VERSION ""

NS_ :

BS_:

BU_: RoomController HomeAssistantESP
VAL_TABLE_ DMAS_VAR_TYPE_TABLE 8 "DMAS_TES" 7 "DMAS_TBS" 6 "DMAS_TF32S" 5 "DMAS_TS32" 4 "DMAS_TS16" 3 "DMAS_TS8" 2 "DMAS_TU32" 1 "DMAS_TU16" 0 "DMAS_TU8" ;
VAL_TABLE_ DMAS_MODE_TABLE 4 "DMAS_MODE_STOPOVERWRITE" 3 "DMAS_MODE_OVERWRITE" 2 "DMAS_MODE_WRITE" 1 "DMAS_MODE_STOP_READ" 0 "DMAS_MODE_READ_REQ" ;
VAL_TABLE_ DMAS_TIME_TABLE 5 "stream 5000ms" 4 "stream 1000ms" 3 "stream 500ms" 2 "stream 100ms" 1 "stream 50ms" 0 "stream 10ms" ;

BO_ 3221225472 VECTOR__INDEPENDENT_SIG_MSG: 0 Vector__XXX
 SG_ DMAS_var_type : 0|8@1+ (1,0) [0|255] "" Vector__XXX

BO_ 48 Lux_Measurement: 8 Vector__XXX
 SG_ Lux : 0|32@1- (1,0) [-3.4E+038|3.4E+038] "" Vector__XXX

BO_ 273 RelayFeedback_64_127: 8 Vector__XXX
 SG_ RelaySts_125 : 63|1@1+ (1,0) [0|1] "" Vector__XXX
 SG_ RelaySts_124 : 62|1@1+ (1,0) [0|1] "" Vector__XXX
 SG_ RelaySts_123 : 61|1@1+ (1,0) [0|1] "" Vector__XXX
 SG_ RelaySts_122 : 60|1@1+ (1,0) [0|1] "" Vector__XXX
 SG_ RelaySts_121 : 59|1@1+ (1,0) [0|1] "" Vector__XXX
 SG_ RelaySts_120 : 58|1@1+ (1,0) [0|1] "" Vector__XXX
 SG_ RelaySts_119 : 57|1@1+ (1,0) [0|1] "" Vector__XXX
 SG_ RelaySts_118 : 56|1@1+ (1,0) [0|1] "" Vector__XXX
 SG_ RelaySts_117 : 55|1@1+ (1,0) [0|1] "" Vector__XXX
 SG_ RelaySts_116 : 54|1@1+ (1,0) [0|1] "" Vector__XXX
 SG_ RelaySts_115 : 53|1@1+ (1,0) [0|1] "" Vector__XXX
 SG_ RelaySts_114 : 52|1@1+ (1,0) [0|1] "" Vector__XXX
 SG_ RelaySts_113 : 51|1@1+ (1,0) [0|1] "" Vector__XXX
 SG_ RelaySts_112 : 50|1@1+ (1,0) [0|1] "" Vector__XXX
 SG_ RelaySts_111 : 49|1@1+ (1,0) [0|1] "" Vector__XXX
 SG_ RelaySts_110 : 48|1@1+ (1,0) [0|1] "" Vector__XXX
 SG_ RelaySts_110 : 47|1@1+ (1,0) [0|1] "" Vector__XXX
 SG_ RelaySts_109 : 46|1@1+ (1,0) [0|1] "" Vector__XXX
 SG_ RelaySts_108 : 45|1@1+ (1,0) [0|1] "" Vector__XXX
 SG_ RelaySts_107 : 44|1@1+ (1,0) [0|1] "" Vector__XXX
 SG_ RelaySts_106 : 43|1@1+ (1,0) [0|1] "" Vector__XXX
 SG_ RelaySts_105 : 42|1@1+ (1,0) [0|1] "" Vector__XXX
 SG_ RelaySts_104 : 41|1@1+ (1,0) [0|1] "" Vector__XXX
 SG_ RelaySts_103 : 40|1@1+ (1,0) [0|1] "" Vector__XXX
 SG_ RelaySts_102 : 39|1@1+ (1,0) [0|1] "" Vector__XXX
 SG_ RelaySts_101 : 38|1@1+ (1,0) [0|1] "" Vector__XXX
 SG_ RelaySts_100 : 37|1@1+ (1,0) [0|1] "" Vector__XXX
 SG_ RelaySts_99 : 36|1@1+ (1,0) [0|1] "" Vector__XXX
 SG_ RelaySts_98 : 35|1@1+ (1,0) [0|1] "" Vector__XXX
 SG_ RelaySts_97 : 34|1@1+ (1,0) [0|1] "" Vector__XXX
 SG_ RelaySts_96 : 33|1@1+ (1,0) [0|1] "" Vector__XXX
 SG_ RelaySts_95 : 32|1@1+ (1,0) [0|1] "" Vector__XXX
 SG_ RelaySts_94 : 31|1@1+ (1,0) [0|1] "" Vector__XXX
 SG_ RelaySts_93 : 30|1@1+ (1,0) [0|1] "" Vector__XXX
 SG_ RelaySts_92 : 29|1@1+ (1,0) [0|1] "" Vector__XXX
 SG_ RelaySts_91 : 28|1@1+ (1,0) [0|1] "" Vector__XXX
 SG_ RelaySts_90 : 27|1@1+ (1,0) [0|1] "" Vector__XXX
 SG_ RelaySts_80 : 26|1@1+ (1,0) [0|1] "" Vector__XXX
 SG_ RelaySts_89 : 25|1@1+ (1,0) [0|1] "" Vector__XXX
 SG_ RelaySts_88 : 24|1@1+ (1,0) [0|1] "" Vector__XXX
 SG_ RelaySts_87 : 23|1@1+ (1,0) [0|1] "" Vector__XXX
 SG_ RelaySts_86 : 22|1@1+ (1,0) [0|1] "" Vector__XXX
 SG_ RelaySts_85 : 21|1@1+ (1,0) [0|1] "" Vector__XXX
 SG_ RelaySts_84 : 20|1@1+ (1,0) [0|1] "" Vector__XXX
 SG_ RelaySts_83 : 19|1@1+ (1,0) [0|1] "" Vector__XXX
 SG_ RelaySts_82 : 18|1@1+ (1,0) [0|1] "" Vector__XXX
 SG_ RelaySts_81 : 17|1@1+ (1,0) [0|1] "" Vector__XXX
 SG_ RelaySts_80 : 16|1@1+ (1,0) [0|1] "" Vector__XXX
 SG_ RelaySts_79 : 15|1@1+ (1,0) [0|1] "" Vector__XXX
 SG_ RelaySts_78 : 14|1@1+ (1,0) [0|1] "" Vector__XXX
 SG_ RelaySts_77 : 13|1@1+ (1,0) [0|1] "" Vector__XXX
 SG_ RelaySts_76 : 12|1@1+ (1,0) [0|1] "" Vector__XXX
 SG_ RelaySts_75 : 11|1@1+ (1,0) [0|1] "" Vector__XXX
 SG_ RelaySts_74 : 10|1@1+ (1,0) [0|1] "" Vector__XXX
 SG_ RelaySts_73 : 9|1@1+ (1,0) [0|1] "" Vector__XXX
 SG_ RelaySts_72 : 8|1@1+ (1,0) [0|1] "" Vector__XXX
 SG_ RelaySts_71 : 7|1@1+ (1,0) [0|1] "" Vector__XXX
 SG_ RelaySts_70 : 6|1@1+ (1,0) [0|1] "" Vector__XXX
 SG_ RelaySts_69 : 5|1@1+ (1,0) [0|1] "" Vector__XXX
 SG_ RelaySts_68 : 4|1@1+ (1,0) [0|1] "" Vector__XXX
 SG_ RelaySts_67 : 3|1@1+ (1,0) [0|1] "" Vector__XXX
 SG_ RelaySts_66 : 2|1@1+ (1,0) [0|1] "" Vector__XXX
 SG_ RelaySts_65 : 1|1@1+ (1,0) [0|1] "" Vector__XXX
 SG_ RelaySts_64 : 0|1@1+ (1,0) [0|1] "" Vector__XXX

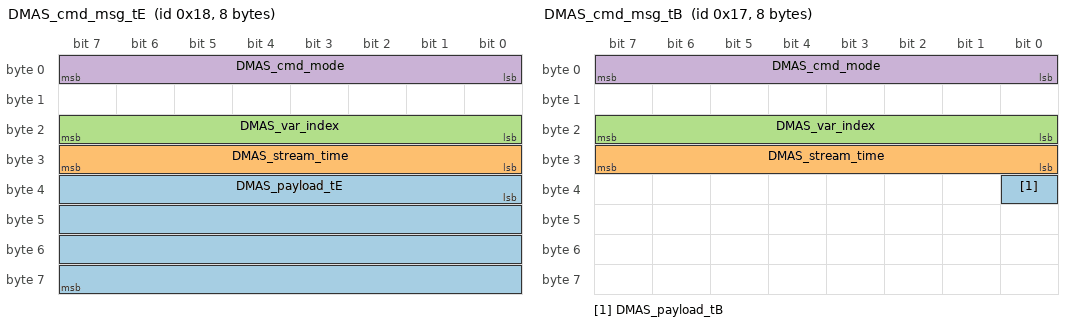
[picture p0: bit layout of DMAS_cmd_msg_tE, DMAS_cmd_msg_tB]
BO_ 24 DMAS_cmd_msg_tE: 8 Vector__XXX
 SG_ DMAS_payload_tE : 32|32@1+ (1,0) [0|4294967295] "" Vector__XXX
 SG_ DMAS_stream_time : 24|8@1+ (1,0) [0|255] "" Vector__XXX
 SG_ DMAS_var_index : 16|8@1+ (1,0) [0|255] "" Vector__XXX
 SG_ DMAS_cmd_mode : 0|8@1+ (1,0) [0|255] "" Vector__XXX

BO_ 23 DMAS_cmd_msg_tB: 8 Vector__XXX
 SG_ DMAS_payload_tB : 32|1@1+ (1,0) [0|1] "" Vector__XXX
 SG_ DMAS_stream_time : 24|8@1+ (1,0) [0|255] "" Vector__XXX
 SG_ DMAS_var_index : 16|8@1+ (1,0) [0|255] "" Vector__XXX
 SG_ DMAS_cmd_mode : 0|8@1+ (1,0) [0|255] "" Vector__XXX

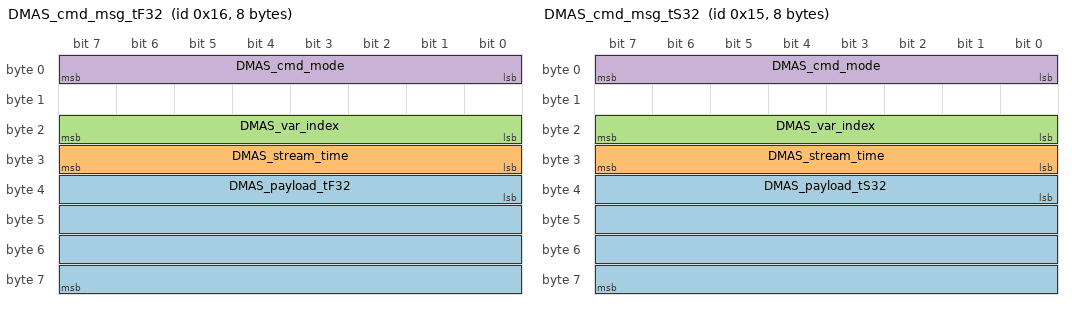
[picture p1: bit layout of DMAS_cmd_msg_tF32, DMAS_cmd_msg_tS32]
BO_ 22 DMAS_cmd_msg_tF32: 8 Vector__XXX
 SG_ DMAS_payload_tF32 : 32|32@1- (1,0) [-3.4E+038|3.4E+038] "" Vector__XXX
 SG_ DMAS_stream_time : 24|8@1+ (1,0) [0|255] "" Vector__XXX
 SG_ DMAS_var_index : 16|8@1+ (1,0) [0|255] "" Vector__XXX
 SG_ DMAS_cmd_mode : 0|8@1+ (1,0) [0|255] "" Vector__XXX

BO_ 21 DMAS_cmd_msg_tS32: 8 Vector__XXX
 SG_ DMAS_payload_tS32 : 32|32@1- (1,0) [-2147483648|2147483647] "" Vector__XXX
 SG_ DMAS_stream_time : 24|8@1+ (1,0) [0|255] "" Vector__XXX
 SG_ DMAS_var_index : 16|8@1+ (1,0) [0|255] "" Vector__XXX
 SG_ DMAS_cmd_mode : 0|8@1+ (1,0) [0|255] "" Vector__XXX

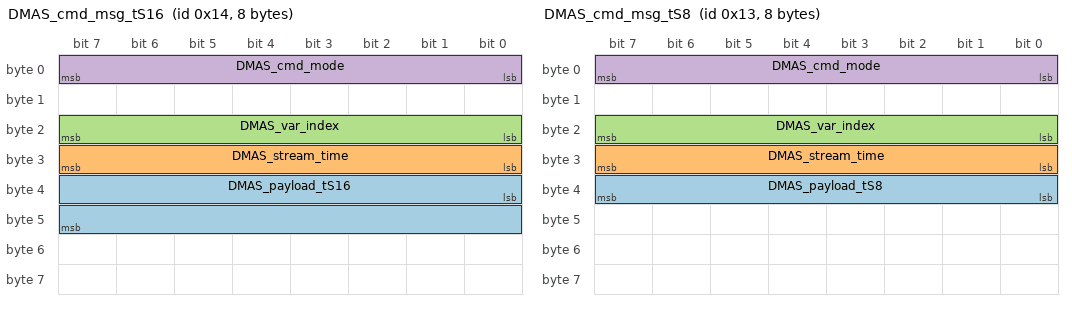
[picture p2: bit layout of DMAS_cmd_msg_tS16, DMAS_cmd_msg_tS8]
BO_ 20 DMAS_cmd_msg_tS16: 8 Vector__XXX
 SG_ DMAS_payload_tS16 : 32|16@1- (1,0) [-32768|32767] "" Vector__XXX
 SG_ DMAS_stream_time : 24|8@1+ (1,0) [0|255] "" Vector__XXX
 SG_ DMAS_var_index : 16|8@1+ (1,0) [0|255] "" Vector__XXX
 SG_ DMAS_cmd_mode : 0|8@1+ (1,0) [0|255] "" Vector__XXX

BO_ 19 DMAS_cmd_msg_tS8: 8 Vector__XXX
 SG_ DMAS_payload_tS8 : 32|8@1- (1,0) [-128|127] "" Vector__XXX
 SG_ DMAS_stream_time : 24|8@1+ (1,0) [0|255] "" Vector__XXX
 SG_ DMAS_var_index : 16|8@1+ (1,0) [0|255] "" Vector__XXX
 SG_ DMAS_cmd_mode : 0|8@1+ (1,0) [0|255] "" Vector__XXX

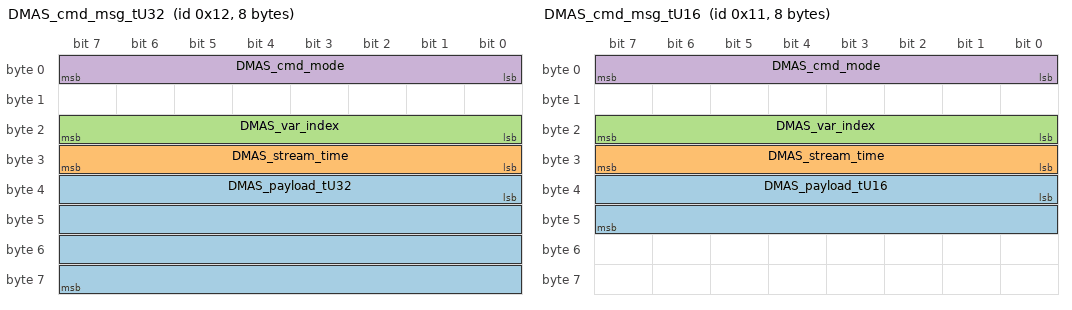
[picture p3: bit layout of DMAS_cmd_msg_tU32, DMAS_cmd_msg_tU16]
BO_ 18 DMAS_cmd_msg_tU32: 8 Vector__XXX
 SG_ DMAS_payload_tU32 : 32|32@1+ (1,0) [0|4294967295] "" Vector__XXX
 SG_ DMAS_stream_time : 24|8@1+ (1,0) [0|255] "" Vector__XXX
 SG_ DMAS_var_index : 16|8@1+ (1,0) [0|255] "" Vector__XXX
 SG_ DMAS_cmd_mode : 0|8@1+ (1,0) [0|255] "" Vector__XXX

BO_ 17 DMAS_cmd_msg_tU16: 8 Vector__XXX
 SG_ DMAS_payload_tU16 : 32|16@1+ (1,0) [0|65535] "" Vector__XXX
 SG_ DMAS_stream_time : 24|8@1+ (1,0) [0|255] "" Vector__XXX
 SG_ DMAS_var_index : 16|8@1+ (1,0) [0|255] "" Vector__XXX
 SG_ DMAS_cmd_mode : 0|8@1+ (1,0) [0|255] "" Vector__XXX

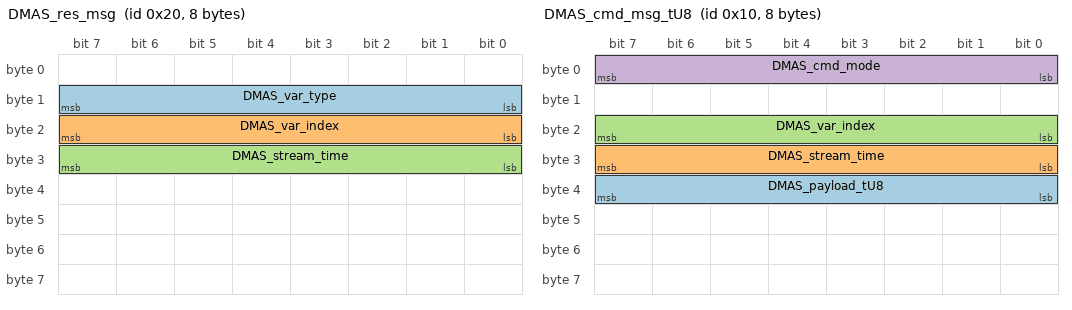
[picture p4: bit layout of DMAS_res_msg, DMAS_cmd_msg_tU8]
BO_ 32 DMAS_res_msg: 8 Vector__XXX
 SG_ DMAS_var_type : 8|8@1+ (1,0) [0|255] "" Vector__XXX
 SG_ DMAS_var_index : 16|8@1+ (1,0) [0|255] "" Vector__XXX
 SG_ DMAS_stream_time : 24|8@1+ (1,0) [0|255] "" Vector__XXX

BO_ 16 DMAS_cmd_msg_tU8: 8 Vector__XXX
 SG_ DMAS_payload_tU8 : 32|8@1+ (1,0) [0|255] "" Vector__XXX
 SG_ DMAS_stream_time : 24|8@1+ (1,0) [0|255] "" Vector__XXX
 SG_ DMAS_var_index : 16|8@1+ (1,0) [0|255] "" Vector__XXX
 SG_ DMAS_cmd_mode : 0|8@1+ (1,0) [0|255] "" Vector__XXX

BO_ 83 Dimmer_errh_msg3: 8 Vector__XXX
 SG_ errh_errLvl : 0|8@1+ (1,0) [0|255] "" Vector__XXX
 SG_ errh_count : 8|8@1+ (1,0) [0|255] "" Vector__XXX

BO_ 82 Dimmer_errh_msg2: 8 Vector__XXX
 SG_ errh_timestamp : 0|64@1- (1,0) [-9.22337203685478E+018|9.22337203685478E+018] "us" Vector__XXX

BO_ 81 Dimmer_errh_msg1: 8 Vector__XXX
 SG_ errh_errId : 32|32@1+ (1,0) [0|0] "" Vector__XXX
 SG_ errh_apiId : 0|32@1+ (1,0) [0|4294967295] "" Vector__XXX

BO_ 80 Dimmer_errh_msg0: 8 Vector__XXX
 SG_ errh_moduleId : 0|32@1+ (1,0) [0|4294967295] "" Vector__XXX
 SG_ errh_instanceId : 32|32@1+ (1,0) [0|4294967295] "" Vector__XXX

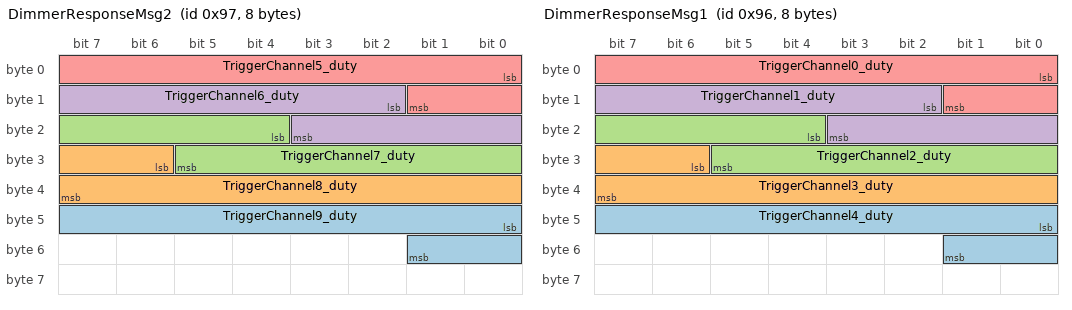
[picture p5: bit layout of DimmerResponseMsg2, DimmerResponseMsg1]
BO_ 151 DimmerResponseMsg2: 8 Vector__XXX
 SG_ TriggerChannel9_duty : 40|10@1+ (1,0) [0|1000] "0.1%" Vector__XXX
 SG_ TriggerChannel8_duty : 30|10@1+ (1,0) [0|1000] "0.1%" Vector__XXX
 SG_ TriggerChannel7_duty : 20|10@1+ (1,0) [0|1000] "0.1%" Vector__XXX
 SG_ TriggerChannel6_duty : 10|10@1+ (1,0) [0|1000] "0.1%" Vector__XXX
 SG_ TriggerChannel5_duty : 0|10@1+ (1,0) [0|1000] "0.1%" Vector__XXX

BO_ 150 DimmerResponseMsg1: 8 Vector__XXX
 SG_ TriggerChannel4_duty : 40|10@1+ (1,0) [0|1000] "0.1%" Vector__XXX
 SG_ TriggerChannel3_duty : 30|10@1+ (1,0) [0|1000] "0.1%" Vector__XXX
 SG_ TriggerChannel2_duty : 20|10@1+ (1,0) [0|1000] "0.1%" Vector__XXX
 SG_ TriggerChannel1_duty : 10|10@1+ (1,0) [0|1000] "0.1%" Vector__XXX
 SG_ TriggerChannel0_duty : 0|10@1+ (1,0) [0|1000] "0.1%" Vector__XXX

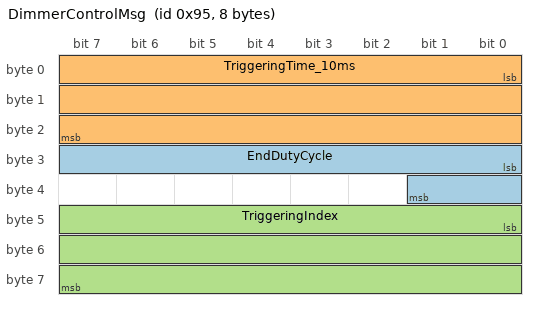
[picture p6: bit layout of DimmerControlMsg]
BO_ 149 DimmerControlMsg: 8 Vector__XXX
 SG_ EndDutyCycle : 24|10@1+ (1,0) [0|1000] "0.1%" Vector__XXX
 SG_ TriggeringTime_10ms : 0|24@1+ (1,0) [0|16777215] "10ms" Vector__XXX
 SG_ TriggeringIndex : 40|24@1+ (1,0) [0|16777215] "" Vector__XXX

BO_ 256 RelayInvrtReq: 8 Vector__XXX
 SG_ Relay_invert_request_63 : 63|1@1+ (1,0) [0|1] "" Vector__XXX
 SG_ Relay_invert_request_62 : 62|1@1+ (1,0) [0|1] "" Vector__XXX
 SG_ Relay_invert_request_61 : 61|1@1+ (1,0) [0|1] "" Vector__XXX
 SG_ Relay_invert_request_60 : 60|1@1+ (1,0) [0|1] "" Vector__XXX
 SG_ Relay_invert_request_59 : 59|1@1+ (1,0) [0|1] "" Vector__XXX
 SG_ Relay_invert_request_58 : 58|1@1+ (1,0) [0|1] "" Vector__XXX
 SG_ Relay_invert_request_57 : 57|1@1+ (1,0) [0|1] "" Vector__XXX
 SG_ Relay_invert_request_56 : 56|1@1+ (1,0) [0|1] "" Vector__XXX
 SG_ Relay_invert_request_55 : 55|1@1+ (1,0) [0|1] "" Vector__XXX
 SG_ Relay_invert_request_54 : 54|1@1+ (1,0) [0|1] "" Vector__XXX
 SG_ Relay_invert_request_53 : 53|1@1+ (1,0) [0|1] "" Vector__XXX
 SG_ Relay_invert_request_52 : 52|1@1+ (1,0) [0|1] "" Vector__XXX
 SG_ Relay_invert_request_51 : 51|1@1+ (1,0) [0|1] "" Vector__XXX
 SG_ Relay_invert_request_50 : 50|1@1+ (1,0) [0|1] "" Vector__XXX
 SG_ Relay_invert_request_49 : 49|1@1+ (1,0) [0|1] "" Vector__XXX
 SG_ Relay_invert_request_48 : 48|1@1+ (1,0) [0|1] "" Vector__XXX
 SG_ Relay_invert_request_47 : 47|1@1+ (1,0) [0|1] "" Vector__XXX
 SG_ Relay_invert_request_46 : 46|1@1+ (1,0) [0|1] "" Vector__XXX
 SG_ Relay_invert_request_45 : 45|1@1+ (1,0) [0|1] "" Vector__XXX
 SG_ Relay_invert_request_44 : 44|1@1+ (1,0) [0|1] "" Vector__XXX
 SG_ Relay_invert_request_43 : 43|1@1+ (1,0) [0|1] "" Vector__XXX
 SG_ Relay_invert_request_42 : 42|1@1+ (1,0) [0|1] "" Vector__XXX
 SG_ Relay_invert_request_41 : 41|1@1+ (1,0) [0|1] "" Vector__XXX
 SG_ Relay_invert_request_40 : 40|1@1+ (1,0) [0|1] "" Vector__XXX
 SG_ Relay_invert_request_39 : 39|1@1+ (1,0) [0|1] "" Vector__XXX
 SG_ Relay_invert_request_38 : 38|1@1+ (1,0) [0|1] "" Vector__XXX
 SG_ Relay_invert_request_37 : 37|1@1+ (1,0) [0|1] "" Vector__XXX
 SG_ Relay_invert_request_36 : 36|1@1+ (1,0) [0|1] "" Vector__XXX
 SG_ Relay_invert_request_35 : 35|1@1+ (1,0) [0|1] "" Vector__XXX
 SG_ Relay_invert_request_34 : 34|1@1+ (1,0) [0|1] "" Vector__XXX
 SG_ Relay_invert_request_33 : 33|1@1+ (1,0) [0|1] "" Vector__XXX
 SG_ Relay_invert_request_32 : 32|1@1+ (1,0) [0|1] "" Vector__XXX
 SG_ Relay_invert_request_31 : 31|1@1+ (1,0) [0|1] "" Vector__XXX
 SG_ Relay_invert_request_30 : 30|1@1+ (1,0) [0|1] "" Vector__XXX
 SG_ Relay_invert_request_29 : 29|1@1+ (1,0) [0|1] "" Vector__XXX
 SG_ Relay_invert_request_28 : 28|1@1+ (1,0) [0|1] "" Vector__XXX
 SG_ Relay_invert_request_27 : 27|1@1+ (1,0) [0|1] "" Vector__XXX
 SG_ Relay_invert_request_26 : 26|1@1+ (1,0) [0|1] "" Vector__XXX
 SG_ Relay_invert_request_25 : 25|1@1+ (1,0) [0|1] "" Vector__XXX
 SG_ Relay_invert_request_24 : 24|1@1+ (1,0) [0|1] "" Vector__XXX
 SG_ Relay_invert_request_23 : 23|1@1+ (1,0) [0|1] "" Vector__XXX
 SG_ Relay_invert_request_22 : 22|1@1+ (1,0) [0|1] "" Vector__XXX
 SG_ Relay_invert_request_21 : 21|1@1+ (1,0) [0|1] "" Vector__XXX
 SG_ Relay_invert_request_20 : 20|1@1+ (1,0) [0|1] "" Vector__XXX
 SG_ Relay_invert_request_19 : 19|1@1+ (1,0) [0|1] "" Vector__XXX
 SG_ Relay_invert_request_18 : 18|1@1+ (1,0) [0|1] "" Vector__XXX
 SG_ Relay_invert_request_17 : 17|1@1+ (1,0) [0|1] "" Vector__XXX
 SG_ Relay_invert_request_16 : 16|1@1+ (1,0) [0|1] "" Vector__XXX
 SG_ Relay_invert_request_15 : 15|1@1+ (1,0) [0|1] "" Vector__XXX
 SG_ Relay_invert_request_14 : 14|1@1+ (1,0) [0|1] "" Vector__XXX
 SG_ Relay_invert_request_13 : 13|1@1+ (1,0) [0|1] "" Vector__XXX
 SG_ Relay_invert_request_12 : 12|1@1+ (1,0) [0|1] "" Vector__XXX
 SG_ Relay_invert_request_11 : 11|1@1+ (1,0) [0|1] "" Vector__XXX
 SG_ Relay_invert_request_10 : 10|1@1+ (1,0) [0|1] "" Vector__XXX
 SG_ Relay_invert_request_09 : 9|1@1+ (1,0) [0|1] "" Vector__XXX
 SG_ Relay_invert_request_08 : 8|1@1+ (1,0) [0|1] "" Vector__XXX
 SG_ Relay_invert_request_07 : 7|1@1+ (1,0) [0|1] "" Vector__XXX
 SG_ Relay_invert_request_06 : 6|1@1+ (1,0) [0|1] "" Vector__XXX
 SG_ Relay_invert_request_05 : 5|1@1+ (1,0) [0|1] "" Vector__XXX
 SG_ Relay_invert_request_04 : 4|1@1+ (1,0) [0|1] "" Vector__XXX
 SG_ Relay_invert_request_03 : 3|1@1+ (1,0) [0|1] "" Vector__XXX
 SG_ Relay_invert_request_02 : 2|1@1+ (1,0) [0|1] "" Vector__XXX
 SG_ Relay_invert_request_01 : 1|1@1+ (1,0) [0|1] "" Vector__XXX
 SG_ Relay_invert_request_00 : 0|1@1+ (1,0) [0|1] "" Vector__XXX

BO_ 261 RelayDisbleReq: 8 Vector__XXX
 SG_ Relay_disable_request_63 : 63|1@1+ (1,0) [0|1] "" Vector__XXX
 SG_ Relay_disable_request_62 : 62|1@1+ (1,0) [0|1] "" Vector__XXX
 SG_ Relay_disable_request_61 : 61|1@1+ (1,0) [0|1] "" Vector__XXX
 SG_ Relay_disable_request_60 : 60|1@1+ (1,0) [0|1] "" Vector__XXX
 SG_ Relay_disable_request_59 : 59|1@1+ (1,0) [0|1] "" Vector__XXX
 SG_ Relay_disable_request_58 : 58|1@1+ (1,0) [0|1] "" Vector__XXX
 SG_ Relay_disable_request_57 : 57|1@1+ (1,0) [0|1] "" Vector__XXX
 SG_ Relay_disable_request_56 : 56|1@1+ (1,0) [0|1] "" Vector__XXX
 SG_ Relay_disable_request_55 : 55|1@1+ (1,0) [0|1] "" Vector__XXX
 SG_ Relay_disable_request_54 : 54|1@1+ (1,0) [0|1] "" Vector__XXX
 SG_ Relay_disable_request_53 : 53|1@1+ (1,0) [0|1] "" Vector__XXX
 SG_ Relay_disable_request_52 : 52|1@1+ (1,0) [0|1] "" Vector__XXX
 SG_ Relay_disable_request_51 : 51|1@1+ (1,0) [0|1] "" Vector__XXX
 SG_ Relay_disable_request_50 : 50|1@1+ (1,0) [0|1] "" Vector__XXX
 SG_ Relay_disable_request_49 : 49|1@1+ (1,0) [0|1] "" Vector__XXX
 SG_ Relay_disable_request_48 : 48|1@1+ (1,0) [0|1] "" Vector__XXX
 SG_ Relay_disable_request_47 : 47|1@1+ (1,0) [0|1] "" Vector__XXX
 SG_ Relay_disable_request_46 : 46|1@1+ (1,0) [0|1] "" Vector__XXX
 SG_ Relay_disable_request_45 : 45|1@1+ (1,0) [0|1] "" Vector__XXX
 SG_ Relay_disable_request_44 : 44|1@1+ (1,0) [0|1] "" Vector__XXX
 SG_ Relay_disable_request_43 : 43|1@1+ (1,0) [0|1] "" Vector__XXX
 SG_ Relay_disable_request_42 : 42|1@1+ (1,0) [0|1] "" Vector__XXX
 SG_ Relay_disable_request_41 : 41|1@1+ (1,0) [0|1] "" Vector__XXX
 SG_ Relay_disable_request_40 : 40|1@1+ (1,0) [0|1] "" Vector__XXX
 SG_ Relay_disable_request_39 : 39|1@1+ (1,0) [0|1] "" Vector__XXX
 SG_ Relay_disable_request_38 : 38|1@1+ (1,0) [0|1] "" Vector__XXX
 SG_ Relay_disable_request_37 : 37|1@1+ (1,0) [0|1] "" Vector__XXX
 SG_ Relay_disable_request_36 : 36|1@1+ (1,0) [0|1] "" Vector__XXX
 SG_ Relay_disable_request_35 : 35|1@1+ (1,0) [0|1] "" Vector__XXX
 SG_ Relay_disable_request_34 : 34|1@1+ (1,0) [0|1] "" Vector__XXX
 SG_ Relay_disable_request_33 : 33|1@1+ (1,0) [0|1] "" Vector__XXX
 SG_ Relay_disable_request_32 : 32|1@1+ (1,0) [0|1] "" Vector__XXX
 SG_ Relay_disable_request_31 : 31|1@1+ (1,0) [0|1] "" Vector__XXX
 SG_ Relay_disable_request_30 : 30|1@1+ (1,0) [0|1] "" Vector__XXX
 SG_ Relay_disable_request_29 : 29|1@1+ (1,0) [0|1] "" Vector__XXX
 SG_ Relay_disable_request_28 : 28|1@1+ (1,0) [0|1] "" Vector__XXX
 SG_ Relay_disable_request_27 : 27|1@1+ (1,0) [0|1] "" Vector__XXX
 SG_ Relay_disable_request_26 : 26|1@1+ (1,0) [0|1] "" Vector__XXX
 SG_ Relay_disable_request_25 : 25|1@1+ (1,0) [0|1] "" Vector__XXX
 SG_ Relay_disable_request_24 : 24|1@1+ (1,0) [0|1] "" Vector__XXX
 SG_ Relay_disable_request_23 : 23|1@1+ (1,0) [0|1] "" Vector__XXX
 SG_ Relay_disable_request_22 : 22|1@1+ (1,0) [0|1] "" Vector__XXX
 SG_ Relay_disable_request_21 : 21|1@1+ (1,0) [0|1] "" Vector__XXX
 SG_ Relay_disable_request_20 : 20|1@1+ (1,0) [0|1] "" Vector__XXX
 SG_ Relay_disable_request_19 : 19|1@1+ (1,0) [0|1] "" Vector__XXX
 SG_ Relay_disable_request_18 : 18|1@1+ (1,0) [0|1] "" Vector__XXX
 SG_ Relay_disable_request_17 : 17|1@1+ (1,0) [0|1] "" Vector__XXX
 SG_ Relay_disable_request_16 : 16|1@1+ (1,0) [0|1] "" Vector__XXX
 SG_ Relay_disable_request_15 : 15|1@1+ (1,0) [0|1] "" Vector__XXX
 SG_ Relay_disable_request_14 : 14|1@1+ (1,0) [0|1] "" Vector__XXX
 SG_ Relay_disable_request_13 : 13|1@1+ (1,0) [0|1] "" Vector__XXX
 SG_ Relay_disable_request_12 : 12|1@1+ (1,0) [0|1] "" Vector__XXX
 SG_ Relay_disable_request_11 : 11|1@1+ (1,0) [0|1] "" Vector__XXX
 SG_ Relay_disable_request_10 : 10|1@1+ (1,0) [0|1] "" Vector__XXX
 SG_ Relay_disable_request_09 : 9|1@1+ (1,0) [0|1] "" Vector__XXX
 SG_ Relay_disable_request_08 : 8|1@1+ (1,0) [0|1] "" Vector__XXX
 SG_ Relay_disable_request_07 : 7|1@1+ (1,0) [0|1] "" Vector__XXX
 SG_ Relay_disable_request_06 : 6|1@1+ (1,0) [0|1] "" Vector__XXX
 SG_ Relay_disable_request_05 : 5|1@1+ (1,0) [0|1] "" Vector__XXX
 SG_ Relay_disable_request_04 : 4|1@1+ (1,0) [0|1] "" Vector__XXX
 SG_ Relay_disable_request_03 : 3|1@1+ (1,0) [0|1] "" Vector__XXX
 SG_ Relay_disable_request_02 : 2|1@1+ (1,0) [0|1] "" Vector__XXX
 SG_ Relay_disable_request_01 : 1|1@1+ (1,0) [0|1] "" Vector__XXX
 SG_ Relay_disable_request_00 : 0|1@1+ (1,0) [0|1] "" Vector__XXX

BO_ 336 GpioSts: 8 Vector__XXX
 SG_ Gpio_State_63 : 63|1@1+ (1,0) [0|1] "" Vector__XXX
 SG_ Gpio_State_62 : 62|1@1+ (1,0) [0|1] "" Vector__XXX
 SG_ Gpio_State_61 : 61|1@1+ (1,0) [0|1] "" Vector__XXX
 SG_ Gpio_State_60 : 60|1@1+ (1,0) [0|1] "" Vector__XXX
 SG_ Gpio_State_59 : 59|1@1+ (1,0) [0|1] "" Vector__XXX
 SG_ Gpio_State_58 : 58|1@1+ (1,0) [0|1] "" Vector__XXX
 SG_ Gpio_State_57 : 57|1@1+ (1,0) [0|1] "" Vector__XXX
 SG_ Gpio_State_56 : 56|1@1+ (1,0) [0|1] "" Vector__XXX
 SG_ Gpio_State_55 : 55|1@1+ (1,0) [0|1] "" Vector__XXX
 SG_ Gpio_State_54 : 54|1@1+ (1,0) [0|1] "" Vector__XXX
 SG_ Gpio_State_53 : 53|1@1+ (1,0) [0|1] "" Vector__XXX
 SG_ Gpio_State_52 : 52|1@1+ (1,0) [0|1] "" Vector__XXX
 SG_ Gpio_State_51 : 51|1@1+ (1,0) [0|1] "" Vector__XXX
 SG_ Gpio_State_50 : 50|1@1+ (1,0) [0|1] "" Vector__XXX
 SG_ Gpio_State_49 : 49|1@1+ (1,0) [0|1] "" Vector__XXX
 SG_ Gpio_State_48 : 48|1@1+ (1,0) [0|1] "" Vector__XXX
 SG_ Gpio_State_47 : 47|1@1+ (1,0) [0|1] "" Vector__XXX
 SG_ Gpio_State_46 : 46|1@1+ (1,0) [0|1] "" Vector__XXX
 SG_ Gpio_State_45 : 45|1@1+ (1,0) [0|1] "" Vector__XXX
 SG_ Gpio_State_44 : 44|1@1+ (1,0) [0|1] "" Vector__XXX
 SG_ Gpio_State_43 : 43|1@1+ (1,0) [0|1] "" Vector__XXX
 SG_ Gpio_State_42 : 42|1@1+ (1,0) [0|1] "" Vector__XXX
 SG_ Gpio_State_41 : 41|1@1+ (1,0) [0|1] "" Vector__XXX
 SG_ Gpio_State_40 : 40|1@1+ (1,0) [0|1] "" Vector__XXX
 SG_ Gpio_State_39 : 39|1@1+ (1,0) [0|1] "" Vector__XXX
 SG_ Gpio_State_38 : 38|1@1+ (1,0) [0|1] "" Vector__XXX
 SG_ Gpio_State_37 : 37|1@1+ (1,0) [0|1] "" Vector__XXX
 SG_ Gpio_State_36 : 36|1@1+ (1,0) [0|1] "" Vector__XXX
 SG_ Gpio_State_35 : 35|1@1+ (1,0) [0|1] "" Vector__XXX
 SG_ Gpio_State_34 : 34|1@1+ (1,0) [0|1] "" Vector__XXX
 SG_ Gpio_State_33 : 33|1@1+ (1,0) [0|1] "" Vector__XXX
 SG_ Gpio_State_32 : 32|1@1+ (1,0) [0|1] "" Vector__XXX
 SG_ Gpio_State_31 : 31|1@1+ (1,0) [0|1] "" Vector__XXX
 SG_ Gpio_State_30 : 30|1@1+ (1,0) [0|1] "" Vector__XXX
 SG_ Gpio_State_29 : 29|1@1+ (1,0) [0|1] "" Vector__XXX
 SG_ Gpio_State_28 : 28|1@1+ (1,0) [0|1] "" Vector__XXX
 SG_ Gpio_State_27 : 27|1@1+ (1,0) [0|1] "" Vector__XXX
 SG_ Gpio_State_26 : 26|1@1+ (1,0) [0|1] "" Vector__XXX
 SG_ Gpio_State_25 : 25|1@1+ (1,0) [0|1] "" Vector__XXX
 SG_ Gpio_State_24 : 24|1@1+ (1,0) [0|1] "" Vector__XXX
 SG_ Gpio_State_23 : 23|1@1+ (1,0) [0|1] "" Vector__XXX
 SG_ Gpio_State_22 : 22|1@1+ (1,0) [0|1] "" Vector__XXX
 SG_ Gpio_State_21 : 21|1@1+ (1,0) [0|1] "" Vector__XXX
 SG_ Gpio_State_20 : 20|1@1+ (1,0) [0|1] "" Vector__XXX
 SG_ Gpio_State_19 : 19|1@1+ (1,0) [0|1] "" Vector__XXX
 SG_ Gpio_State_18 : 18|1@1+ (1,0) [0|1] "" Vector__XXX
 SG_ Gpio_State_17 : 17|1@1+ (1,0) [0|1] "" Vector__XXX
 SG_ Gpio_State_16 : 16|1@1+ (1,0) [0|1] "" Vector__XXX
 SG_ Gpio_State_15 : 15|1@1+ (1,0) [0|1] "" Vector__XXX
 SG_ Gpio_State_14 : 14|1@1+ (1,0) [0|1] "" Vector__XXX
 SG_ Gpio_State_13 : 13|1@1+ (1,0) [0|1] "" Vector__XXX
 SG_ Gpio_State_12 : 12|1@1+ (1,0) [0|1] "" Vector__XXX
 SG_ Gpio_State_11 : 11|1@1+ (1,0) [0|1] "" Vector__XXX
 SG_ Gpio_State_10 : 10|1@1+ (1,0) [0|1] "" Vector__XXX
 SG_ Gpio_State_09 : 9|1@1+ (1,0) [0|1] "" Vector__XXX
 SG_ Gpio_State_08 : 8|1@1+ (1,0) [0|1] "" Vector__XXX
 SG_ Gpio_State_07 : 7|1@1+ (1,0) [0|1] "" Vector__XXX
 SG_ Gpio_State_06 : 6|1@1+ (1,0) [0|1] "" Vector__XXX
 SG_ Gpio_State_05 : 5|1@1+ (1,0) [0|1] "" Vector__XXX
 SG_ Gpio_State_04 : 4|1@1+ (1,0) [0|1] "" Vector__XXX
 SG_ Gpio_State_03 : 3|1@1+ (1,0) [0|1] "" Vector__XXX
 SG_ Gpio_State_02 : 2|1@1+ (1,0) [0|1] "" Vector__XXX
 SG_ Gpio_State_01 : 1|1@1+ (1,0) [0|1] "" Vector__XXX
 SG_ Gpio_State_00 : 0|1@1+ (1,0) [0|1] "" Vector__XXX

BO_ 272 RelayFeedback_0_63: 8 Vector__XXX
 SG_ RelaySts_63 : 63|1@1+ (1,0) [0|1] "" Vector__XXX
 SG_ RelaySts_62 : 62|1@1+ (1,0) [0|1] "" Vector__XXX
 SG_ RelaySts_61 : 61|1@1+ (1,0) [0|1] "" Vector__XXX
 SG_ RelaySts_60 : 60|1@1+ (1,0) [0|1] "" Vector__XXX
 SG_ RelaySts_59 : 59|1@1+ (1,0) [0|1] "" Vector__XXX
 SG_ RelaySts_58 : 58|1@1+ (1,0) [0|1] "" Vector__XXX
 SG_ RelaySts_57 : 57|1@1+ (1,0) [0|1] "" Vector__XXX
 SG_ RelaySts_56 : 56|1@1+ (1,0) [0|1] "" Vector__XXX
 SG_ RelaySts_55 : 55|1@1+ (1,0) [0|1] "" Vector__XXX
 SG_ RelaySts_54 : 54|1@1+ (1,0) [0|1] "" Vector__XXX
 SG_ RelaySts_53 : 53|1@1+ (1,0) [0|1] "" Vector__XXX
 SG_ RelaySts_52 : 52|1@1+ (1,0) [0|1] "" Vector__XXX
 SG_ RelaySts_51 : 51|1@1+ (1,0) [0|1] "" Vector__XXX
 SG_ RelaySts_50 : 50|1@1+ (1,0) [0|1] "" Vector__XXX
 SG_ RelaySts_49 : 49|1@1+ (1,0) [0|1] "" Vector__XXX
 SG_ RelaySts_48 : 48|1@1+ (1,0) [0|1] "" Vector__XXX
 SG_ RelaySts_47 : 47|1@1+ (1,0) [0|1] "" Vector__XXX
 SG_ RelaySts_46 : 46|1@1+ (1,0) [0|1] "" Vector__XXX
 SG_ RelaySts_45 : 45|1@1+ (1,0) [0|1] "" Vector__XXX
 SG_ RelaySts_44 : 44|1@1+ (1,0) [0|1] "" Vector__XXX
 SG_ RelaySts_43 : 43|1@1+ (1,0) [0|1] "" Vector__XXX
 SG_ RelaySts_42 : 42|1@1+ (1,0) [0|1] "" Vector__XXX
 SG_ RelaySts_41 : 41|1@1+ (1,0) [0|1] "" Vector__XXX
 SG_ RelaySts_40 : 40|1@1+ (1,0) [0|1] "" Vector__XXX
 SG_ RelaySts_39 : 39|1@1+ (1,0) [0|1] "" Vector__XXX
 SG_ RelaySts_38 : 38|1@1+ (1,0) [0|1] "" Vector__XXX
 SG_ RelaySts_37 : 37|1@1+ (1,0) [0|1] "" Vector__XXX
 SG_ RelaySts_36 : 36|1@1+ (1,0) [0|1] "" Vector__XXX
 SG_ RelaySts_35 : 35|1@1+ (1,0) [0|1] "" Vector__XXX
 SG_ RelaySts_34 : 34|1@1+ (1,0) [0|1] "" Vector__XXX
 SG_ RelaySts_33 : 33|1@1+ (1,0) [0|1] "" Vector__XXX
 SG_ RelaySts_32 : 32|1@1+ (1,0) [0|1] "" Vector__XXX
 SG_ RelaySts_31 : 31|1@1+ (1,0) [0|1] "" Vector__XXX
 SG_ RelaySts_30 : 30|1@1+ (1,0) [0|1] "" Vector__XXX
 SG_ RelaySts_29 : 29|1@1+ (1,0) [0|1] "" Vector__XXX
 SG_ RelaySts_28 : 28|1@1+ (1,0) [0|1] "" Vector__XXX
 SG_ RelaySts_27 : 27|1@1+ (1,0) [0|1] "" Vector__XXX
 SG_ RelaySts_26 : 26|1@1+ (1,0) [0|1] "" Vector__XXX
 SG_ RelaySts_25 : 25|1@1+ (1,0) [0|1] "" Vector__XXX
 SG_ RelaySts_24 : 24|1@1+ (1,0) [0|1] "" Vector__XXX
 SG_ RelaySts_23 : 23|1@1+ (1,0) [0|1] "" Vector__XXX
 SG_ RelaySts_22 : 22|1@1+ (1,0) [0|1] "" Vector__XXX
 SG_ RelaySts_21 : 21|1@1+ (1,0) [0|1] "" Vector__XXX
 SG_ RelaySts_20 : 20|1@1+ (1,0) [0|1] "" Vector__XXX
 SG_ RelaySts_19 : 19|1@1+ (1,0) [0|1] "" Vector__XXX
 SG_ RelaySts_18 : 18|1@1+ (1,0) [0|1] "" Vector__XXX
 SG_ RelaySts_17 : 17|1@1+ (1,0) [0|1] "" Vector__XXX
 SG_ RelaySts_16 : 16|1@1+ (1,0) [0|1] "" Vector__XXX
 SG_ RelaySts_15 : 15|1@1+ (1,0) [0|1] "" Vector__XXX
 SG_ RelaySts_14 : 14|1@1+ (1,0) [0|1] "" Vector__XXX
 SG_ RelaySts_13 : 13|1@1+ (1,0) [0|1] "" Vector__XXX
 SG_ RelaySts_12 : 12|1@1+ (1,0) [0|1] "" Vector__XXX
 SG_ RelaySts_11 : 11|1@1+ (1,0) [0|1] "" Vector__XXX
 SG_ RelaySts_10 : 10|1@1+ (1,0) [0|1] "" Vector__XXX
 SG_ RelaySts_09 : 9|1@1+ (1,0) [0|1] "" Vector__XXX
 SG_ RelaySts_08 : 8|1@1+ (1,0) [0|1] "" Vector__XXX
 SG_ RelaySts_07 : 7|1@1+ (1,0) [0|1] "" Vector__XXX
 SG_ RelaySts_06 : 6|1@1+ (1,0) [0|1] "" Vector__XXX
 SG_ RelaySts_05 : 5|1@1+ (1,0) [0|1] "" Vector__XXX
 SG_ RelaySts_04 : 4|1@1+ (1,0) [0|1] "" Vector__XXX
 SG_ RelaySts_03 : 3|1@1+ (1,0) [0|1] "" Vector__XXX
 SG_ RelaySts_02 : 2|1@1+ (1,0) [0|1] "" Vector__XXX
 SG_ RelaySts_01 : 1|1@1+ (1,0) [0|1] "" Vector__XXX
 SG_ RelaySts_00 : 0|1@1+ (1,0) [0|1] "" Vector__XXX

BO_ 511 RC_SDM120M_1_10: 8 Vector__XXX
 SG_ TotalReactEnrgy_kVArh : 0|32@1- (1,0) [-3.4E+038|3.4E+038] "kVArh" Vector__XXX

BO_ 510 RC_SDM120M_1_9: 8 Vector__XXX
 SG_ TotalActvEnergy_kWh : 32|32@1- (1,0) [-3.4E+038|3.4E+038] "kWh" Vector__XXX
 SG_ MaxCurrDmnd_A : 0|32@1- (1,0) [-3.4E+038|3.4E+038] "A" Vector__XXX

BO_ 509 RC_SDM120M_1_8: 8 Vector__XXX
 SG_ CurrDmnd_A : 32|32@1- (1,0) [-3.4E+038|3.4E+038] "A" Vector__XXX
 SG_ MaxExportSysPwrDmnd_W : 0|32@1- (1,0) [-3.4E+038|3.4E+038] "W" Vector__XXX

BO_ 508 RC_SDM120M_1_7: 8 Vector__XXX
 SG_ ExportSysPwrDmnd_W : 32|32@1- (1,0) [-3.4E+038|3.4E+038] "W" Vector__XXX
 SG_ MaxImportSysPwrDmnd_W : 0|32@1- (1,0) [-3.4E+038|3.4E+038] "W" Vector__XXX

BO_ 507 RC_SDM120M_1_6: 8 Vector__XXX
 SG_ ImportSysPwrDmnd_W : 32|32@1- (1,0) [-3.4E+038|3.4E+038] "W" Vector__XXX
 SG_ MaxTotalSysPwrDmnd_W : 0|32@1- (1,0) [-3.4E+038|3.4E+038] "W" Vector__XXX

BO_ 506 RC_SDM120M_1_5: 8 Vector__XXX
 SG_ TotalSysPwrDmnd_W : 32|32@1- (1,0) [-3.4E+038|3.4E+038] "W" Vector__XXX
 SG_ ExportReactEnrgy_kVArh : 0|32@1- (1,0) [-3.4E+038|3.4E+038] "kVArh" Vector__XXX

BO_ 505 RC_SDM120M_1_4: 8 Vector__XXX
 SG_ ImportReactEnrgy_kVArh : 32|32@1- (1,0) [-3.4E+038|3.4E+038] "kVArh" Vector__XXX
 SG_ ExportActEnrgy_kWh : 0|32@1- (1,0) [-3.4E+038|3.4E+038] "kWh" Vector__XXX

BO_ 504 RC_SDM120M_1_3: 8 Vector__XXX
 SG_ ImportActEnrgy_kWh : 32|32@1- (1,0) [-3.4E+038|3.4E+038] "kWh" Vector__XXX
 SG_ Frequency_Hz : 0|32@1- (1,0) [-3.4E+038|3.4E+038] "Hz" Vector__XXX

BO_ 503 RC_SDM120M_1_2: 8 Vector__XXX
 SG_ PwrFctr : 32|32@1- (1,0) [-3.4E+038|3.4E+038] "" Vector__XXX
 SG_ ReactPwr_VAr : 0|32@1- (1,0) [-3.4E+038|3.4E+038] "VAr" Vector__XXX

BO_ 502 RC_SDM120M_1_1: 8 Vector__XXX
 SG_ AprntPwr_VA : 32|32@1- (1,0) [-3.4E+038|3.4E+038] "VA" Vector__XXX
 SG_ ActivePwr_W : 0|32@1- (1,0) [-3.4E+038|3.4E+038] "W" Vector__XXX

BO_ 501 RC_SDM120M_1_0: 8 RoomController
 SG_ Current_A : 32|32@1- (1,0) [-3.4E+038|3.4E+038] "A" Vector__XXX
 SG_ Voltage_V : 0|32@1- (1,0) [-3.4E+038|3.4E+038] "V" Vector__XXX

BO_ 522 RC_SDM120M_2_10: 8 Vector__XXX
 SG_ TotalReactEnrgy_kVArh : 0|32@1- (1,0) [-3.4E+038|3.4E+038] "kVArh" Vector__XXX

BO_ 521 RC_SDM120M_2_9: 8 Vector__XXX
 SG_ TotalActvEnergy_kWh : 32|32@1- (1,0) [-3.4E+038|3.4E+038] "kWh" Vector__XXX
 SG_ MaxCurrDmnd_A : 0|32@1- (1,0) [-3.4E+038|3.4E+038] "A" Vector__XXX

BO_ 520 RC_SDM120M_2_8: 8 Vector__XXX
 SG_ CurrDmnd_A : 32|32@1- (1,0) [-3.4E+038|3.4E+038] "A" Vector__XXX
 SG_ MaxExportSysPwrDmnd_W : 0|32@1- (1,0) [-3.4E+038|3.4E+038] "W" Vector__XXX

BO_ 519 RC_SDM120M_2_7: 8 Vector__XXX
 SG_ ExportSysPwrDmnd_W : 32|32@1- (1,0) [-3.4E+038|3.4E+038] "W" Vector__XXX
 SG_ MaxImportSysPwrDmnd_W : 0|32@1- (1,0) [-3.4E+038|3.4E+038] "W" Vector__XXX

BO_ 518 RC_SDM120M_2_6: 8 Vector__XXX
 SG_ ImportSysPwrDmnd_W : 32|32@1- (1,0) [-3.4E+038|3.4E+038] "W" Vector__XXX
 SG_ MaxTotalSysPwrDmnd_W : 0|32@1- (1,0) [-3.4E+038|3.4E+038] "W" Vector__XXX

BO_ 517 RC_SDM120M_2_5: 8 Vector__XXX
 SG_ TotalSysPwrDmnd_W : 32|32@1- (1,0) [-3.4E+038|3.4E+038] "W" Vector__XXX
 SG_ ExportReactEnrgy_kVArh : 0|32@1- (1,0) [-3.4E+038|3.4E+038] "kVArh" Vector__XXX

BO_ 516 RC_SDM120M_2_4: 8 Vector__XXX
 SG_ ImportReactEnrgy_kVArh : 32|32@1- (1,0) [-3.4E+038|3.4E+038] "kVArh" Vector__XXX
 SG_ ExportActEnrgy_kWh : 0|32@1- (1,0) [-3.4E+038|3.4E+038] "kWh" Vector__XXX

BO_ 515 RC_SDM120M_2_3: 8 Vector__XXX
 SG_ ImportActEnrgy_kWh : 32|32@1- (1,0) [-3.4E+038|3.4E+038] "kWh" Vector__XXX
 SG_ Frequency_Hz : 0|32@1- (1,0) [-3.4E+038|3.4E+038] "Hz" Vector__XXX

BO_ 514 RC_SDM120M_2_2: 8 Vector__XXX
 SG_ PwrFctr : 32|32@1- (1,0) [-3.4E+038|3.4E+038] "" Vector__XXX
 SG_ ReactPwr_VAr : 0|32@1- (1,0) [-3.4E+038|3.4E+038] "VAr" Vector__XXX

BO_ 513 RC_SDM120M_2_1: 8 Vector__XXX
 SG_ AprntPwr_VA : 32|32@1- (1,0) [-3.4E+038|3.4E+038] "VA" Vector__XXX
 SG_ ActivePwr_W : 0|32@1- (1,0) [-3.4E+038|3.4E+038] "W" Vector__XXX

BO_ 512 RC_SDM120M_2_0: 8 RoomController
 SG_ Current_A : 32|32@1- (1,0) [-3.4E+038|3.4E+038] "A" Vector__XXX
 SG_ Voltage_V : 0|32@1- (1,0) [-3.4E+038|3.4E+038] "V" Vector__XXX

BO_ 533 RC_SDM120M_3_10: 8 Vector__XXX
 SG_ TotalReactEnrgy_kVArh : 0|32@1- (1,0) [-3.4E+038|3.4E+038] "kVArh" Vector__XXX

BO_ 532 RC_SDM120M_3_9: 8 Vector__XXX
 SG_ TotalActvEnergy_kWh : 32|32@1- (1,0) [-3.4E+038|3.4E+038] "kWh" Vector__XXX
 SG_ MaxCurrDmnd_A : 0|32@1- (1,0) [-3.4E+038|3.4E+038] "A" Vector__XXX

BO_ 531 RC_SDM120M_3_8: 8 Vector__XXX
 SG_ CurrDmnd_A : 32|32@1- (1,0) [-3.4E+038|3.4E+038] "A" Vector__XXX
 SG_ MaxExportSysPwrDmnd_W : 0|32@1- (1,0) [-3.4E+038|3.4E+038] "W" Vector__XXX

BO_ 530 RC_SDM120M_3_7: 8 Vector__XXX
 SG_ ExportSysPwrDmnd_W : 32|32@1- (1,0) [-3.4E+038|3.4E+038] "W" Vector__XXX
 SG_ MaxImportSysPwrDmnd_W : 0|32@1- (1,0) [-3.4E+038|3.4E+038] "W" Vector__XXX

BO_ 529 RC_SDM120M_3_6: 8 Vector__XXX
 SG_ ImportSysPwrDmnd_W : 32|32@1- (1,0) [-3.4E+038|3.4E+038] "W" Vector__XXX
 SG_ MaxTotalSysPwrDmnd_W : 0|32@1- (1,0) [-3.4E+038|3.4E+038] "W" Vector__XXX

BO_ 528 RC_SDM120M_3_5: 8 Vector__XXX
 SG_ TotalSysPwrDmnd_W : 32|32@1- (1,0) [-3.4E+038|3.4E+038] "W" Vector__XXX
 SG_ ExportReactEnrgy_kVArh : 0|32@1- (1,0) [-3.4E+038|3.4E+038] "kVArh" Vector__XXX

BO_ 527 RC_SDM120M_3_4: 8 Vector__XXX
 SG_ ImportReactEnrgy_kVArh : 32|32@1- (1,0) [-3.4E+038|3.4E+038] "kVArh" Vector__XXX
 SG_ ExportActEnrgy_kWh : 0|32@1- (1,0) [-3.4E+038|3.4E+038] "kWh" Vector__XXX

BO_ 526 RC_SDM120M_3_3: 8 Vector__XXX
 SG_ ImportActEnrgy_kWh : 32|32@1- (1,0) [-3.4E+038|3.4E+038] "kWh" Vector__XXX
 SG_ Frequency_Hz : 0|32@1- (1,0) [-3.4E+038|3.4E+038] "Hz" Vector__XXX

BO_ 525 RC_SDM120M_3_2: 8 Vector__XXX
 SG_ PwrFctr : 32|32@1- (1,0) [-3.4E+038|3.4E+038] "" Vector__XXX
 SG_ ReactPwr_VAr : 0|32@1- (1,0) [-3.4E+038|3.4E+038] "VAr" Vector__XXX

BO_ 524 RC_SDM120M_3_1: 8 Vector__XXX
 SG_ AprntPwr_VA : 32|32@1- (1,0) [-3.4E+038|3.4E+038] "VA" Vector__XXX
 SG_ ActivePwr_W : 0|32@1- (1,0) [-3.4E+038|3.4E+038] "W" Vector__XXX

BO_ 523 RC_SDM120M_3_0: 8 RoomController
 SG_ Current_A : 32|32@1- (1,0) [-3.4E+038|3.4E+038] "A" Vector__XXX
 SG_ Voltage_V : 0|32@1- (1,0) [-3.4E+038|3.4E+038] "V" Vector__XXX

BO_ 544 RC_SDM120M_4_10: 8 Vector__XXX
 SG_ TotalReactEnrgy_kVArh : 0|32@1- (1,0) [-3.4E+038|3.4E+038] "kVArh" Vector__XXX

BO_ 543 RC_SDM120M_4_9: 8 Vector__XXX
 SG_ TotalActvEnergy_kWh : 32|32@1- (1,0) [-3.4E+038|3.4E+038] "kWh" Vector__XXX
 SG_ MaxCurrDmnd_A : 0|32@1- (1,0) [-3.4E+038|3.4E+038] "A" Vector__XXX

BO_ 542 RC_SDM120M_4_8: 8 Vector__XXX
 SG_ CurrDmnd_A : 32|32@1- (1,0) [-3.4E+038|3.4E+038] "A" Vector__XXX
 SG_ MaxExportSysPwrDmnd_W : 0|32@1- (1,0) [-3.4E+038|3.4E+038] "W" Vector__XXX

BO_ 541 RC_SDM120M_4_7: 8 Vector__XXX
 SG_ ExportSysPwrDmnd_W : 32|32@1- (1,0) [-3.4E+038|3.4E+038] "W" Vector__XXX
 SG_ MaxImportSysPwrDmnd_W : 0|32@1- (1,0) [-3.4E+038|3.4E+038] "W" Vector__XXX

BO_ 540 RC_SDM120M_4_6: 8 Vector__XXX
 SG_ ImportSysPwrDmnd_W : 32|32@1- (1,0) [-3.4E+038|3.4E+038] "W" Vector__XXX
 SG_ MaxTotalSysPwrDmnd_W : 0|32@1- (1,0) [-3.4E+038|3.4E+038] "W" Vector__XXX

BO_ 539 RC_SDM120M_4_5: 8 Vector__XXX
 SG_ TotalSysPwrDmnd_W : 32|32@1- (1,0) [-3.4E+038|3.4E+038] "W" Vector__XXX
 SG_ ExportReactEnrgy_kVArh : 0|32@1- (1,0) [-3.4E+038|3.4E+038] "kVArh" Vector__XXX

BO_ 538 RC_SDM120M_4_4: 8 Vector__XXX
 SG_ ImportReactEnrgy_kVArh : 32|32@1- (1,0) [-3.4E+038|3.4E+038] "kVArh" Vector__XXX
 SG_ ExportActEnrgy_kWh : 0|32@1- (1,0) [-3.4E+038|3.4E+038] "kWh" Vector__XXX

BO_ 537 RC_SDM120M_4_3: 8 Vector__XXX
 SG_ ImportActEnrgy_kWh : 32|32@1- (1,0) [-3.4E+038|3.4E+038] "kWh" Vector__XXX
 SG_ Frequency_Hz : 0|32@1- (1,0) [-3.4E+038|3.4E+038] "Hz" Vector__XXX

BO_ 536 RC_SDM120M_4_2: 8 Vector__XXX
 SG_ PwrFctr : 32|32@1- (1,0) [-3.4E+038|3.4E+038] "" Vector__XXX
 SG_ ReactPwr_VAr : 0|32@1- (1,0) [-3.4E+038|3.4E+038] "VAr" Vector__XXX

BO_ 535 RC_SDM120M_4_1: 8 Vector__XXX
 SG_ AprntPwr_VA : 32|32@1- (1,0) [-3.4E+038|3.4E+038] "VA" Vector__XXX
 SG_ ActivePwr_W : 0|32@1- (1,0) [-3.4E+038|3.4E+038] "W" Vector__XXX

BO_ 534 RC_SDM120M_4_0: 8 RoomController
 SG_ Current_A : 32|32@1- (1,0) [-3.4E+038|3.4E+038] "A" Vector__XXX
 SG_ Voltage_V : 0|32@1- (1,0) [-3.4E+038|3.4E+038] "V" Vector__XXX

BO_ 555 RC_SDM120M_5_10: 8 Vector__XXX
 SG_ TotalReactEnrgy_kVArh : 0|32@1- (1,0) [-3.4E+038|3.4E+038] "kVArh" Vector__XXX

BO_ 554 RC_SDM120M_5_9: 8 Vector__XXX
 SG_ TotalActvEnergy_kWh : 32|32@1- (1,0) [-3.4E+038|3.4E+038] "kWh" Vector__XXX
 SG_ MaxCurrDmnd_A : 0|32@1- (1,0) [-3.4E+038|3.4E+038] "A" Vector__XXX

BO_ 553 RC_SDM120M_5_8: 8 Vector__XXX
 SG_ CurrDmnd_A : 32|32@1- (1,0) [-3.4E+038|3.4E+038] "A" Vector__XXX
 SG_ MaxExportSysPwrDmnd_W : 0|32@1- (1,0) [-3.4E+038|3.4E+038] "W" Vector__XXX

BO_ 552 RC_SDM120M_5_7: 8 Vector__XXX
 SG_ ExportSysPwrDmnd_W : 32|32@1- (1,0) [-3.4E+038|3.4E+038] "W" Vector__XXX
 SG_ MaxImportSysPwrDmnd_W : 0|32@1- (1,0) [-3.4E+038|3.4E+038] "W" Vector__XXX

BO_ 551 RC_SDM120M_5_6: 8 Vector__XXX
 SG_ ImportSysPwrDmnd_W : 32|32@1- (1,0) [-3.4E+038|3.4E+038] "W" Vector__XXX
 SG_ MaxTotalSysPwrDmnd_W : 0|32@1- (1,0) [-3.4E+038|3.4E+038] "W" Vector__XXX

BO_ 550 RC_SDM120M_5_5: 8 Vector__XXX
 SG_ TotalSysPwrDmnd_W : 32|32@1- (1,0) [-3.4E+038|3.4E+038] "W" Vector__XXX
 SG_ ExportReactEnrgy_kVArh : 0|32@1- (1,0) [-3.4E+038|3.4E+038] "kVArh" Vector__XXX

BO_ 549 RC_SDM120M_5_4: 8 Vector__XXX
 SG_ ImportReactEnrgy_kVArh : 32|32@1- (1,0) [-3.4E+038|3.4E+038] "kVArh" Vector__XXX
 SG_ ExportActEnrgy_kWh : 0|32@1- (1,0) [-3.4E+038|3.4E+038] "kWh" Vector__XXX

BO_ 548 RC_SDM120M_5_3: 8 Vector__XXX
 SG_ ImportActEnrgy_kWh : 32|32@1- (1,0) [-3.4E+038|3.4E+038] "kWh" Vector__XXX
 SG_ Frequency_Hz : 0|32@1- (1,0) [-3.4E+038|3.4E+038] "Hz" Vector__XXX

BO_ 547 RC_SDM120M_5_2: 8 Vector__XXX
 SG_ PwrFctr : 32|32@1- (1,0) [-3.4E+038|3.4E+038] "" Vector__XXX
 SG_ ReactPwr_VAr : 0|32@1- (1,0) [-3.4E+038|3.4E+038] "VAr" Vector__XXX

BO_ 546 RC_SDM120M_5_1: 8 Vector__XXX
 SG_ AprntPwr_VA : 32|32@1- (1,0) [-3.4E+038|3.4E+038] "VA" Vector__XXX
 SG_ ActivePwr_W : 0|32@1- (1,0) [-3.4E+038|3.4E+038] "W" Vector__XXX

BO_ 545 RC_SDM120M_5_0: 8 RoomController
 SG_ Current_A : 32|32@1- (1,0) [-3.4E+038|3.4E+038] "A" Vector__XXX
 SG_ Voltage_V : 0|32@1- (1,0) [-3.4E+038|3.4E+038] "V" Vector__XXX

BO_ 566 RC_SDM120M_6_10: 8 Vector__XXX
 SG_ TotalReactEnrgy_kVArh : 0|32@1- (1,0) [-3.4E+038|3.4E+038] "kVArh" Vector__XXX

BO_ 565 RC_SDM120M_6_9: 8 Vector__XXX
 SG_ TotalActvEnergy_kWh : 32|32@1- (1,0) [-3.4E+038|3.4E+038] "kWh" Vector__XXX
 SG_ MaxCurrDmnd_A : 0|32@1- (1,0) [-3.4E+038|3.4E+038] "A" Vector__XXX

BO_ 564 RC_SDM120M_6_8: 8 Vector__XXX
 SG_ CurrDmnd_A : 32|32@1- (1,0) [-3.4E+038|3.4E+038] "A" Vector__XXX
 SG_ MaxExportSysPwrDmnd_W : 0|32@1- (1,0) [-3.4E+038|3.4E+038] "W" Vector__XXX

BO_ 563 RC_SDM120M_6_7: 8 Vector__XXX
 SG_ ExportSysPwrDmnd_W : 32|32@1- (1,0) [-3.4E+038|3.4E+038] "W" Vector__XXX
 SG_ MaxImportSysPwrDmnd_W : 0|32@1- (1,0) [-3.4E+038|3.4E+038] "W" Vector__XXX

BO_ 562 RC_SDM120M_6_6: 8 Vector__XXX
 SG_ ImportSysPwrDmnd_W : 32|32@1- (1,0) [-3.4E+038|3.4E+038] "W" Vector__XXX
 SG_ MaxTotalSysPwrDmnd_W : 0|32@1- (1,0) [-3.4E+038|3.4E+038] "W" Vector__XXX

BO_ 561 RC_SDM120M_6_5: 8 Vector__XXX
 SG_ TotalSysPwrDmnd_W : 32|32@1- (1,0) [-3.4E+038|3.4E+038] "W" Vector__XXX
 SG_ ExportReactEnrgy_kVArh : 0|32@1- (1,0) [-3.4E+038|3.4E+038] "kVArh" Vector__XXX

BO_ 560 RC_SDM120M_6_4: 8 Vector__XXX
 SG_ ImportReactEnrgy_kVArh : 32|32@1- (1,0) [-3.4E+038|3.4E+038] "kVArh" Vector__XXX
 SG_ ExportActEnrgy_kWh : 0|32@1- (1,0) [-3.4E+038|3.4E+038] "kWh" Vector__XXX

BO_ 559 RC_SDM120M_6_3: 8 Vector__XXX
 SG_ ImportActEnrgy_kWh : 32|32@1- (1,0) [-3.4E+038|3.4E+038] "kWh" Vector__XXX
 SG_ Frequency_Hz : 0|32@1- (1,0) [-3.4E+038|3.4E+038] "Hz" Vector__XXX

BO_ 558 RC_SDM120M_6_2: 8 Vector__XXX
 SG_ PwrFctr : 32|32@1- (1,0) [-3.4E+038|3.4E+038] "" Vector__XXX
 SG_ ReactPwr_VAr : 0|32@1- (1,0) [-3.4E+038|3.4E+038] "VAr" Vector__XXX

BO_ 557 RC_SDM120M_6_1: 8 Vector__XXX
 SG_ AprntPwr_VA : 32|32@1- (1,0) [-3.4E+038|3.4E+038] "VA" Vector__XXX
 SG_ ActivePwr_W : 0|32@1- (1,0) [-3.4E+038|3.4E+038] "W" Vector__XXX

BO_ 556 RC_SDM120M_6_0: 8 RoomController
 SG_ Current_A : 32|32@1- (1,0) [-3.4E+038|3.4E+038] "A" Vector__XXX
 SG_ Voltage_V : 0|32@1- (1,0) [-3.4E+038|3.4E+038] "V" Vector__XXX

BO_ 577 RC_SDM120M_7_10: 8 Vector__XXX
 SG_ TotalReactEnrgy_kVArh : 0|32@1- (1,0) [-3.4E+038|3.4E+038] "kVArh" Vector__XXX

BO_ 576 RC_SDM120M_7_9: 8 Vector__XXX
 SG_ TotalActvEnergy_kWh : 32|32@1- (1,0) [-3.4E+038|3.4E+038] "kWh" Vector__XXX
 SG_ MaxCurrDmnd_A : 0|32@1- (1,0) [-3.4E+038|3.4E+038] "A" Vector__XXX

BO_ 575 RC_SDM120M_7_8: 8 Vector__XXX
 SG_ CurrDmnd_A : 32|32@1- (1,0) [-3.4E+038|3.4E+038] "A" Vector__XXX
 SG_ MaxExportSysPwrDmnd_W : 0|32@1- (1,0) [-3.4E+038|3.4E+038] "W" Vector__XXX

BO_ 574 RC_SDM120M_7_7: 8 Vector__XXX
 SG_ ExportSysPwrDmnd_W : 32|32@1- (1,0) [-3.4E+038|3.4E+038] "W" Vector__XXX
 SG_ MaxImportSysPwrDmnd_W : 0|32@1- (1,0) [-3.4E+038|3.4E+038] "W" Vector__XXX

BO_ 573 RC_SDM120M_7_6: 8 Vector__XXX
 SG_ ImportSysPwrDmnd_W : 32|32@1- (1,0) [-3.4E+038|3.4E+038] "W" Vector__XXX
 SG_ MaxTotalSysPwrDmnd_W : 0|32@1- (1,0) [-3.4E+038|3.4E+038] "W" Vector__XXX

BO_ 572 RC_SDM120M_7_5: 8 Vector__XXX
 SG_ TotalSysPwrDmnd_W : 32|32@1- (1,0) [-3.4E+038|3.4E+038] "W" Vector__XXX
 SG_ ExportReactEnrgy_kVArh : 0|32@1- (1,0) [-3.4E+038|3.4E+038] "kVArh" Vector__XXX

BO_ 571 RC_SDM120M_7_4: 8 Vector__XXX
 SG_ ImportReactEnrgy_kVArh : 32|32@1- (1,0) [-3.4E+038|3.4E+038] "kVArh" Vector__XXX
 SG_ ExportActEnrgy_kWh : 0|32@1- (1,0) [-3.4E+038|3.4E+038] "kWh" Vector__XXX

BO_ 570 RC_SDM120M_7_3: 8 Vector__XXX
 SG_ ImportActEnrgy_kWh : 32|32@1- (1,0) [-3.4E+038|3.4E+038] "kWh" Vector__XXX
 SG_ Frequency_Hz : 0|32@1- (1,0) [-3.4E+038|3.4E+038] "Hz" Vector__XXX

BO_ 569 RC_SDM120M_7_2: 8 Vector__XXX
 SG_ PwrFctr : 32|32@1- (1,0) [-3.4E+038|3.4E+038] "" Vector__XXX
 SG_ ReactPwr_VAr : 0|32@1- (1,0) [-3.4E+038|3.4E+038] "VAr" Vector__XXX

BO_ 568 RC_SDM120M_7_1: 8 Vector__XXX
 SG_ AprntPwr_VA : 32|32@1- (1,0) [-3.4E+038|3.4E+038] "VA" Vector__XXX
 SG_ ActivePwr_W : 0|32@1- (1,0) [-3.4E+038|3.4E+038] "W" Vector__XXX

BO_ 567 RC_SDM120M_7_0: 8 RoomController
 SG_ Current_A : 32|32@1- (1,0) [-3.4E+038|3.4E+038] "A" Vector__XXX
 SG_ Voltage_V : 0|32@1- (1,0) [-3.4E+038|3.4E+038] "V" Vector__XXX

BO_ 588 RC_SDM120M_8_10: 8 Vector__XXX
 SG_ TotalReactEnrgy_kVArh : 0|32@1- (1,0) [-3.4E+038|3.4E+038] "kVArh" Vector__XXX

BO_ 587 RC_SDM120M_8_9: 8 Vector__XXX
 SG_ TotalActvEnergy_kWh : 32|32@1- (1,0) [-3.4E+038|3.4E+038] "kWh" Vector__XXX
 SG_ MaxCurrDmnd_A : 0|32@1- (1,0) [-3.4E+038|3.4E+038] "A" Vector__XXX

BO_ 586 RC_SDM120M_8_8: 8 Vector__XXX
 SG_ CurrDmnd_A : 32|32@1- (1,0) [-3.4E+038|3.4E+038] "A" Vector__XXX
 SG_ MaxExportSysPwrDmnd_W : 0|32@1- (1,0) [-3.4E+038|3.4E+038] "W" Vector__XXX

BO_ 585 RC_SDM120M_8_7: 8 Vector__XXX
 SG_ ExportSysPwrDmnd_W : 32|32@1- (1,0) [-3.4E+038|3.4E+038] "W" Vector__XXX
 SG_ MaxImportSysPwrDmnd_W : 0|32@1- (1,0) [-3.4E+038|3.4E+038] "W" Vector__XXX

BO_ 584 RC_SDM120M_8_6: 8 Vector__XXX
 SG_ ImportSysPwrDmnd_W : 32|32@1- (1,0) [-3.4E+038|3.4E+038] "W" Vector__XXX
 SG_ MaxTotalSysPwrDmnd_W : 0|32@1- (1,0) [-3.4E+038|3.4E+038] "W" Vector__XXX

BO_ 583 RC_SDM120M_8_5: 8 Vector__XXX
 SG_ TotalSysPwrDmnd_W : 32|32@1- (1,0) [-3.4E+038|3.4E+038] "W" Vector__XXX
 SG_ ExportReactEnrgy_kVArh : 0|32@1- (1,0) [-3.4E+038|3.4E+038] "kVArh" Vector__XXX

BO_ 582 RC_SDM120M_8_4: 8 Vector__XXX
 SG_ ImportReactEnrgy_kVArh : 32|32@1- (1,0) [-3.4E+038|3.4E+038] "kVArh" Vector__XXX
 SG_ ExportActEnrgy_kWh : 0|32@1- (1,0) [-3.4E+038|3.4E+038] "kWh" Vector__XXX

BO_ 581 RC_SDM120M_8_3: 8 Vector__XXX
 SG_ ImportActEnrgy_kWh : 32|32@1- (1,0) [-3.4E+038|3.4E+038] "kWh" Vector__XXX
 SG_ Frequency_Hz : 0|32@1- (1,0) [-3.4E+038|3.4E+038] "Hz" Vector__XXX

BO_ 580 RC_SDM120M_8_2: 8 Vector__XXX
 SG_ PwrFctr : 32|32@1- (1,0) [-3.4E+038|3.4E+038] "" Vector__XXX
 SG_ ReactPwr_VAr : 0|32@1- (1,0) [-3.4E+038|3.4E+038] "VAr" Vector__XXX

BO_ 579 RC_SDM120M_8_1: 8 Vector__XXX
 SG_ AprntPwr_VA : 32|32@1- (1,0) [-3.4E+038|3.4E+038] "VA" Vector__XXX
 SG_ ActivePwr_W : 0|32@1- (1,0) [-3.4E+038|3.4E+038] "W" Vector__XXX

BO_ 578 RC_SDM120M_8_0: 8 RoomController
 SG_ Current_A : 32|32@1- (1,0) [-3.4E+038|3.4E+038] "A" Vector__XXX
 SG_ Voltage_V : 0|32@1- (1,0) [-3.4E+038|3.4E+038] "V" Vector__XXX

BO_ 599 RC_SDM120M_9_10: 8 Vector__XXX
 SG_ TotalReactEnrgy_kVArh : 0|32@1- (1,0) [-3.4E+038|3.4E+038] "kVArh" Vector__XXX

BO_ 598 RC_SDM120M_9_9: 8 Vector__XXX
 SG_ TotalActvEnergy_kWh : 32|32@1- (1,0) [-3.4E+038|3.4E+038] "kWh" Vector__XXX
 SG_ MaxCurrDmnd_A : 0|32@1- (1,0) [-3.4E+038|3.4E+038] "A" Vector__XXX

BO_ 597 RC_SDM120M_9_8: 8 Vector__XXX
 SG_ CurrDmnd_A : 32|32@1- (1,0) [-3.4E+038|3.4E+038] "A" Vector__XXX
 SG_ MaxExportSysPwrDmnd_W : 0|32@1- (1,0) [-3.4E+038|3.4E+038] "W" Vector__XXX

BO_ 596 RC_SDM120M_9_7: 8 Vector__XXX
 SG_ ExportSysPwrDmnd_W : 32|32@1- (1,0) [-3.4E+038|3.4E+038] "W" Vector__XXX
 SG_ MaxImportSysPwrDmnd_W : 0|32@1- (1,0) [-3.4E+038|3.4E+038] "W" Vector__XXX

BO_ 595 RC_SDM120M_9_6: 8 Vector__XXX
 SG_ ImportSysPwrDmnd_W : 32|32@1- (1,0) [-3.4E+038|3.4E+038] "W" Vector__XXX
 SG_ MaxTotalSysPwrDmnd_W : 0|32@1- (1,0) [-3.4E+038|3.4E+038] "W" Vector__XXX

BO_ 594 RC_SDM120M_9_5: 8 Vector__XXX
 SG_ TotalSysPwrDmnd_W : 32|32@1- (1,0) [-3.4E+038|3.4E+038] "W" Vector__XXX
 SG_ ExportReactEnrgy_kVArh : 0|32@1- (1,0) [-3.4E+038|3.4E+038] "kVArh" Vector__XXX

BO_ 593 RC_SDM120M_9_4: 8 Vector__XXX
 SG_ ImportReactEnrgy_kVArh : 32|32@1- (1,0) [-3.4E+038|3.4E+038] "kVArh" Vector__XXX
 SG_ ExportActEnrgy_kWh : 0|32@1- (1,0) [-3.4E+038|3.4E+038] "kWh" Vector__XXX

BO_ 592 RC_SDM120M_9_3: 8 Vector__XXX
 SG_ ImportActEnrgy_kWh : 32|32@1- (1,0) [-3.4E+038|3.4E+038] "kWh" Vector__XXX
 SG_ Frequency_Hz : 0|32@1- (1,0) [-3.4E+038|3.4E+038] "Hz" Vector__XXX

BO_ 591 RC_SDM120M_9_2: 8 Vector__XXX
 SG_ PwrFctr : 32|32@1- (1,0) [-3.4E+038|3.4E+038] "" Vector__XXX
 SG_ ReactPwr_VAr : 0|32@1- (1,0) [-3.4E+038|3.4E+038] "VAr" Vector__XXX

BO_ 590 RC_SDM120M_9_1: 8 Vector__XXX
 SG_ AprntPwr_VA : 32|32@1- (1,0) [-3.4E+038|3.4E+038] "VA" Vector__XXX
 SG_ ActivePwr_W : 0|32@1- (1,0) [-3.4E+038|3.4E+038] "W" Vector__XXX

BO_ 589 RC_SDM120M_9_0: 8 RoomController
 SG_ Current_A : 32|32@1- (1,0) [-3.4E+038|3.4E+038] "A" Vector__XXX
 SG_ Voltage_V : 0|32@1- (1,0) [-3.4E+038|3.4E+038] "V" Vector__XXX

BO_ 610 RC_SDM120M_10_10: 8 Vector__XXX
 SG_ TotalReactEnrgy_kVArh : 0|32@1- (1,0) [-3.4E+038|3.4E+038] "kVArh" Vector__XXX

BO_ 609 RC_SDM120M_10_9: 8 Vector__XXX
 SG_ TotalActvEnergy_kWh : 32|32@1- (1,0) [-3.4E+038|3.4E+038] "kWh" Vector__XXX
 SG_ MaxCurrDmnd_A : 0|32@1- (1,0) [-3.4E+038|3.4E+038] "A" Vector__XXX

BO_ 608 RC_SDM120M_10_8: 8 Vector__XXX
 SG_ CurrDmnd_A : 32|32@1- (1,0) [-3.4E+038|3.4E+038] "A" Vector__XXX
 SG_ MaxExportSysPwrDmnd_W : 0|32@1- (1,0) [-3.4E+038|3.4E+038] "W" Vector__XXX

BO_ 607 RC_SDM120M_10_7: 8 Vector__XXX
 SG_ ExportSysPwrDmnd_W : 32|32@1- (1,0) [-3.4E+038|3.4E+038] "W" Vector__XXX
 SG_ MaxImportSysPwrDmnd_W : 0|32@1- (1,0) [-3.4E+038|3.4E+038] "W" Vector__XXX

BO_ 606 RC_SDM120M_10_6: 8 Vector__XXX
 SG_ ImportSysPwrDmnd_W : 32|32@1- (1,0) [-3.4E+038|3.4E+038] "W" Vector__XXX
 SG_ MaxTotalSysPwrDmnd_W : 0|32@1- (1,0) [-3.4E+038|3.4E+038] "W" Vector__XXX

BO_ 605 RC_SDM120M_10_5: 8 Vector__XXX
 SG_ TotalSysPwrDmnd_W : 32|32@1- (1,0) [-3.4E+038|3.4E+038] "W" Vector__XXX
 SG_ ExportReactEnrgy_kVArh : 0|32@1- (1,0) [-3.4E+038|3.4E+038] "kVArh" Vector__XXX

BO_ 604 RC_SDM120M_10_4: 8 Vector__XXX
 SG_ ImportReactEnrgy_kVArh : 32|32@1- (1,0) [-3.4E+038|3.4E+038] "kVArh" Vector__XXX
 SG_ ExportActEnrgy_kWh : 0|32@1- (1,0) [-3.4E+038|3.4E+038] "kWh" Vector__XXX

BO_ 603 RC_SDM120M_10_3: 8 Vector__XXX
 SG_ ImportActEnrgy_kWh : 32|32@1- (1,0) [-3.4E+038|3.4E+038] "kWh" Vector__XXX
 SG_ Frequency_Hz : 0|32@1- (1,0) [-3.4E+038|3.4E+038] "Hz" Vector__XXX

BO_ 602 RC_SDM120M_10_2: 8 Vector__XXX
 SG_ PwrFctr : 32|32@1- (1,0) [-3.4E+038|3.4E+038] "" Vector__XXX
 SG_ ReactPwr_VAr : 0|32@1- (1,0) [-3.4E+038|3.4E+038] "VAr" Vector__XXX

BO_ 601 RC_SDM120M_10_1: 8 Vector__XXX
 SG_ AprntPwr_VA : 32|32@1- (1,0) [-3.4E+038|3.4E+038] "VA" Vector__XXX
 SG_ ActivePwr_W : 0|32@1- (1,0) [-3.4E+038|3.4E+038] "W" Vector__XXX

BO_ 600 RC_SDM120M_10_0: 8 RoomController
 SG_ Current_A : 32|32@1- (1,0) [-3.4E+038|3.4E+038] "A" Vector__XXX
 SG_ Voltage_V : 0|32@1- (1,0) [-3.4E+038|3.4E+038] "V" Vector__XXX

BO_ 621 RC_SDM120M_11_10: 8 Vector__XXX
 SG_ TotalReactEnrgy_kVArh : 0|32@1- (1,0) [-3.4E+038|3.4E+038] "kVArh" Vector__XXX

BO_ 620 RC_SDM120M_11_9: 8 Vector__XXX
 SG_ TotalActvEnergy_kWh : 32|32@1- (1,0) [-3.4E+038|3.4E+038] "kWh" Vector__XXX
 SG_ MaxCurrDmnd_A : 0|32@1- (1,0) [-3.4E+038|3.4E+038] "A" Vector__XXX

BO_ 619 RC_SDM120M_11_8: 8 Vector__XXX
 SG_ CurrDmnd_A : 32|32@1- (1,0) [-3.4E+038|3.4E+038] "A" Vector__XXX
 SG_ MaxExportSysPwrDmnd_W : 0|32@1- (1,0) [-3.4E+038|3.4E+038] "W" Vector__XXX

BO_ 618 RC_SDM120M_11_7: 8 Vector__XXX
 SG_ ExportSysPwrDmnd_W : 32|32@1- (1,0) [-3.4E+038|3.4E+038] "W" Vector__XXX
 SG_ MaxImportSysPwrDmnd_W : 0|32@1- (1,0) [-3.4E+038|3.4E+038] "W" Vector__XXX

BO_ 617 RC_SDM120M_11_6: 8 Vector__XXX
 SG_ ImportSysPwrDmnd_W : 32|32@1- (1,0) [-3.4E+038|3.4E+038] "W" Vector__XXX
 SG_ MaxTotalSysPwrDmnd_W : 0|32@1- (1,0) [-3.4E+038|3.4E+038] "W" Vector__XXX

BO_ 616 RC_SDM120M_11_5: 8 Vector__XXX
 SG_ TotalSysPwrDmnd_W : 32|32@1- (1,0) [-3.4E+038|3.4E+038] "W" Vector__XXX
 SG_ ExportReactEnrgy_kVArh : 0|32@1- (1,0) [-3.4E+038|3.4E+038] "kVArh" Vector__XXX

BO_ 615 RC_SDM120M_11_4: 8 Vector__XXX
 SG_ ImportReactEnrgy_kVArh : 32|32@1- (1,0) [-3.4E+038|3.4E+038] "kVArh" Vector__XXX
 SG_ ExportActEnrgy_kWh : 0|32@1- (1,0) [-3.4E+038|3.4E+038] "kWh" Vector__XXX

BO_ 614 RC_SDM120M_11_3: 8 Vector__XXX
 SG_ ImportActEnrgy_kWh : 32|32@1- (1,0) [-3.4E+038|3.4E+038] "kWh" Vector__XXX
 SG_ Frequency_Hz : 0|32@1- (1,0) [-3.4E+038|3.4E+038] "Hz" Vector__XXX

BO_ 613 RC_SDM120M_11_2: 8 Vector__XXX
 SG_ PwrFctr : 32|32@1- (1,0) [-3.4E+038|3.4E+038] "" Vector__XXX
 SG_ ReactPwr_VAr : 0|32@1- (1,0) [-3.4E+038|3.4E+038] "VAr" Vector__XXX

BO_ 612 RC_SDM120M_11_1: 8 Vector__XXX
 SG_ AprntPwr_VA : 32|32@1- (1,0) [-3.4E+038|3.4E+038] "VA" Vector__XXX
 SG_ ActivePwr_W : 0|32@1- (1,0) [-3.4E+038|3.4E+038] "W" Vector__XXX

BO_ 611 RC_SDM120M_11_0: 8 RoomController
 SG_ Current_A : 32|32@1- (1,0) [-3.4E+038|3.4E+038] "A" Vector__XXX
 SG_ Voltage_V : 0|32@1- (1,0) [-3.4E+038|3.4E+038] "V" Vector__XXX

BO_ 632 RC_SDM120M_12_10: 8 Vector__XXX
 SG_ TotalReactEnrgy_kVArh : 0|32@1- (1,0) [-3.4E+038|3.4E+038] "kVArh" Vector__XXX

BO_ 631 RC_SDM120M_12_9: 8 Vector__XXX
 SG_ TotalActvEnergy_kWh : 32|32@1- (1,0) [-3.4E+038|3.4E+038] "kWh" Vector__XXX
 SG_ MaxCurrDmnd_A : 0|32@1- (1,0) [-3.4E+038|3.4E+038] "A" Vector__XXX

BO_ 630 RC_SDM120M_12_8: 8 Vector__XXX
 SG_ CurrDmnd_A : 32|32@1- (1,0) [-3.4E+038|3.4E+038] "A" Vector__XXX
 SG_ MaxExportSysPwrDmnd_W : 0|32@1- (1,0) [-3.4E+038|3.4E+038] "W" Vector__XXX

BO_ 629 RC_SDM120M_12_7: 8 Vector__XXX
 SG_ ExportSysPwrDmnd_W : 32|32@1- (1,0) [-3.4E+038|3.4E+038] "W" Vector__XXX
 SG_ MaxImportSysPwrDmnd_W : 0|32@1- (1,0) [-3.4E+038|3.4E+038] "W" Vector__XXX

BO_ 628 RC_SDM120M_12_6: 8 Vector__XXX
 SG_ ImportSysPwrDmnd_W : 32|32@1- (1,0) [-3.4E+038|3.4E+038] "W" Vector__XXX
 SG_ MaxTotalSysPwrDmnd_W : 0|32@1- (1,0) [-3.4E+038|3.4E+038] "W" Vector__XXX

BO_ 627 RC_SDM120M_12_5: 8 Vector__XXX
 SG_ TotalSysPwrDmnd_W : 32|32@1- (1,0) [-3.4E+038|3.4E+038] "W" Vector__XXX
 SG_ ExportReactEnrgy_kVArh : 0|32@1- (1,0) [-3.4E+038|3.4E+038] "kVArh" Vector__XXX

BO_ 626 RC_SDM120M_12_4: 8 Vector__XXX
 SG_ ImportReactEnrgy_kVArh : 32|32@1- (1,0) [-3.4E+038|3.4E+038] "kVArh" Vector__XXX
 SG_ ExportActEnrgy_kWh : 0|32@1- (1,0) [-3.4E+038|3.4E+038] "kWh" Vector__XXX

BO_ 625 RC_SDM120M_12_3: 8 Vector__XXX
 SG_ ImportActEnrgy_kWh : 32|32@1- (1,0) [-3.4E+038|3.4E+038] "kWh" Vector__XXX
 SG_ Frequency_Hz : 0|32@1- (1,0) [-3.4E+038|3.4E+038] "Hz" Vector__XXX

BO_ 624 RC_SDM120M_12_2: 8 Vector__XXX
 SG_ PwrFctr : 32|32@1- (1,0) [-3.4E+038|3.4E+038] "" Vector__XXX
 SG_ ReactPwr_VAr : 0|32@1- (1,0) [-3.4E+038|3.4E+038] "VAr" Vector__XXX

BO_ 623 RC_SDM120M_12_1: 8 Vector__XXX
 SG_ AprntPwr_VA : 32|32@1- (1,0) [-3.4E+038|3.4E+038] "VA" Vector__XXX
 SG_ ActivePwr_W : 0|32@1- (1,0) [-3.4E+038|3.4E+038] "W" Vector__XXX

BO_ 622 RC_SDM120M_12_0: 8 RoomController
 SG_ Current_A : 32|32@1- (1,0) [-3.4E+038|3.4E+038] "A" Vector__XXX
 SG_ Voltage_V : 0|32@1- (1,0) [-3.4E+038|3.4E+038] "V" Vector__XXX

BO_ 643 RC_SDM120M_13_10: 8 Vector__XXX
 SG_ TotalReactEnrgy_kVArh : 0|32@1- (1,0) [-3.4E+038|3.4E+038] "kVArh" Vector__XXX

BO_ 642 RC_SDM120M_13_9: 8 Vector__XXX
 SG_ TotalActvEnergy_kWh : 32|32@1- (1,0) [-3.4E+038|3.4E+038] "kWh" Vector__XXX
 SG_ MaxCurrDmnd_A : 0|32@1- (1,0) [-3.4E+038|3.4E+038] "A" Vector__XXX

BO_ 641 RC_SDM120M_13_8: 8 Vector__XXX
 SG_ CurrDmnd_A : 32|32@1- (1,0) [-3.4E+038|3.4E+038] "A" Vector__XXX
 SG_ MaxExportSysPwrDmnd_W : 0|32@1- (1,0) [-3.4E+038|3.4E+038] "W" Vector__XXX

BO_ 640 RC_SDM120M_13_7: 8 Vector__XXX
 SG_ ExportSysPwrDmnd_W : 32|32@1- (1,0) [-3.4E+038|3.4E+038] "W" Vector__XXX
 SG_ MaxImportSysPwrDmnd_W : 0|32@1- (1,0) [-3.4E+038|3.4E+038] "W" Vector__XXX

BO_ 639 RC_SDM120M_13_6: 8 Vector__XXX
 SG_ ImportSysPwrDmnd_W : 32|32@1- (1,0) [-3.4E+038|3.4E+038] "W" Vector__XXX
 SG_ MaxTotalSysPwrDmnd_W : 0|32@1- (1,0) [-3.4E+038|3.4E+038] "W" Vector__XXX

BO_ 638 RC_SDM120M_13_5: 8 Vector__XXX
 SG_ TotalSysPwrDmnd_W : 32|32@1- (1,0) [-3.4E+038|3.4E+038] "W" Vector__XXX
 SG_ ExportReactEnrgy_kVArh : 0|32@1- (1,0) [-3.4E+038|3.4E+038] "kVArh" Vector__XXX

BO_ 637 RC_SDM120M_13_4: 8 Vector__XXX
 SG_ ImportReactEnrgy_kVArh : 32|32@1- (1,0) [-3.4E+038|3.4E+038] "kVArh" Vector__XXX
 SG_ ExportActEnrgy_kWh : 0|32@1- (1,0) [-3.4E+038|3.4E+038] "kWh" Vector__XXX

BO_ 636 RC_SDM120M_13_3: 8 Vector__XXX
 SG_ ImportActEnrgy_kWh : 32|32@1- (1,0) [-3.4E+038|3.4E+038] "kWh" Vector__XXX
 SG_ Frequency_Hz : 0|32@1- (1,0) [-3.4E+038|3.4E+038] "Hz" Vector__XXX

BO_ 635 RC_SDM120M_13_2: 8 Vector__XXX
 SG_ PwrFctr : 32|32@1- (1,0) [-3.4E+038|3.4E+038] "" Vector__XXX
 SG_ ReactPwr_VAr : 0|32@1- (1,0) [-3.4E+038|3.4E+038] "VAr" Vector__XXX

BO_ 634 RC_SDM120M_13_1: 8 Vector__XXX
 SG_ AprntPwr_VA : 32|32@1- (1,0) [-3.4E+038|3.4E+038] "VA" Vector__XXX
 SG_ ActivePwr_W : 0|32@1- (1,0) [-3.4E+038|3.4E+038] "W" Vector__XXX

BO_ 633 RC_SDM120M_13_0: 8 RoomController
 SG_ Current_A : 32|32@1- (1,0) [-3.4E+038|3.4E+038] "A" Vector__XXX
 SG_ Voltage_V : 0|32@1- (1,0) [-3.4E+038|3.4E+038] "V" Vector__XXX

BO_ 654 RC_SDM120M_14_10: 8 Vector__XXX
 SG_ TotalReactEnrgy_kVArh : 0|32@1- (1,0) [-3.4E+038|3.4E+038] "kVArh" Vector__XXX

BO_ 653 RC_SDM120M_14_9: 8 Vector__XXX
 SG_ TotalActvEnergy_kWh : 32|32@1- (1,0) [-3.4E+038|3.4E+038] "kWh" Vector__XXX
 SG_ MaxCurrDmnd_A : 0|32@1- (1,0) [-3.4E+038|3.4E+038] "A" Vector__XXX

BO_ 652 RC_SDM120M_14_8: 8 Vector__XXX
 SG_ CurrDmnd_A : 32|32@1- (1,0) [-3.4E+038|3.4E+038] "A" Vector__XXX
 SG_ MaxExportSysPwrDmnd_W : 0|32@1- (1,0) [-3.4E+038|3.4E+038] "W" Vector__XXX

BO_ 651 RC_SDM120M_14_7: 8 Vector__XXX
 SG_ ExportSysPwrDmnd_W : 32|32@1- (1,0) [-3.4E+038|3.4E+038] "W" Vector__XXX
 SG_ MaxImportSysPwrDmnd_W : 0|32@1- (1,0) [-3.4E+038|3.4E+038] "W" Vector__XXX

BO_ 650 RC_SDM120M_14_6: 8 Vector__XXX
 SG_ ImportSysPwrDmnd_W : 32|32@1- (1,0) [-3.4E+038|3.4E+038] "W" Vector__XXX
 SG_ MaxTotalSysPwrDmnd_W : 0|32@1- (1,0) [-3.4E+038|3.4E+038] "W" Vector__XXX

BO_ 649 RC_SDM120M_14_5: 8 Vector__XXX
 SG_ TotalSysPwrDmnd_W : 32|32@1- (1,0) [-3.4E+038|3.4E+038] "W" Vector__XXX
 SG_ ExportReactEnrgy_kVArh : 0|32@1- (1,0) [-3.4E+038|3.4E+038] "kVArh" Vector__XXX

BO_ 648 RC_SDM120M_14_4: 8 Vector__XXX
 SG_ ImportReactEnrgy_kVArh : 32|32@1- (1,0) [-3.4E+038|3.4E+038] "kVArh" Vector__XXX
 SG_ ExportActEnrgy_kWh : 0|32@1- (1,0) [-3.4E+038|3.4E+038] "kWh" Vector__XXX

BO_ 647 RC_SDM120M_14_3: 8 Vector__XXX
 SG_ ImportActEnrgy_kWh : 32|32@1- (1,0) [-3.4E+038|3.4E+038] "kWh" Vector__XXX
 SG_ Frequency_Hz : 0|32@1- (1,0) [-3.4E+038|3.4E+038] "Hz" Vector__XXX

BO_ 646 RC_SDM120M_14_2: 8 Vector__XXX
 SG_ PwrFctr : 32|32@1- (1,0) [-3.4E+038|3.4E+038] "" Vector__XXX
 SG_ ReactPwr_VAr : 0|32@1- (1,0) [-3.4E+038|3.4E+038] "VAr" Vector__XXX

BO_ 645 RC_SDM120M_14_1: 8 Vector__XXX
 SG_ AprntPwr_VA : 32|32@1- (1,0) [-3.4E+038|3.4E+038] "VA" Vector__XXX
 SG_ ActivePwr_W : 0|32@1- (1,0) [-3.4E+038|3.4E+038] "W" Vector__XXX

BO_ 644 RC_SDM120M_14_0: 8 RoomController
 SG_ Current_A : 32|32@1- (1,0) [-3.4E+038|3.4E+038] "A" Vector__XXX
 SG_ Voltage_V : 0|32@1- (1,0) [-3.4E+038|3.4E+038] "V" Vector__XXX

BO_ 665 RC_SDM120M_15_10: 8 Vector__XXX
 SG_ TotalReactEnrgy_kVArh : 0|32@1- (1,0) [-3.4E+038|3.4E+038] "kVArh" Vector__XXX

BO_ 664 RC_SDM120M_15_9: 8 Vector__XXX
 SG_ TotalActvEnergy_kWh : 32|32@1- (1,0) [-3.4E+038|3.4E+038] "kWh" Vector__XXX
 SG_ MaxCurrDmnd_A : 0|32@1- (1,0) [-3.4E+038|3.4E+038] "A" Vector__XXX

BO_ 663 RC_SDM120M_15_8: 8 Vector__XXX
 SG_ CurrDmnd_A : 32|32@1- (1,0) [-3.4E+038|3.4E+038] "A" Vector__XXX
 SG_ MaxExportSysPwrDmnd_W : 0|32@1- (1,0) [-3.4E+038|3.4E+038] "W" Vector__XXX

BO_ 662 RC_SDM120M_15_7: 8 Vector__XXX
 SG_ ExportSysPwrDmnd_W : 32|32@1- (1,0) [-3.4E+038|3.4E+038] "W" Vector__XXX
 SG_ MaxImportSysPwrDmnd_W : 0|32@1- (1,0) [-3.4E+038|3.4E+038] "W" Vector__XXX

BO_ 661 RC_SDM120M_15_6: 8 Vector__XXX
 SG_ ImportSysPwrDmnd_W : 32|32@1- (1,0) [-3.4E+038|3.4E+038] "W" Vector__XXX
 SG_ MaxTotalSysPwrDmnd_W : 0|32@1- (1,0) [-3.4E+038|3.4E+038] "W" Vector__XXX

BO_ 660 RC_SDM120M_15_5: 8 Vector__XXX
 SG_ TotalSysPwrDmnd_W : 32|32@1- (1,0) [-3.4E+038|3.4E+038] "W" Vector__XXX
 SG_ ExportReactEnrgy_kVArh : 0|32@1- (1,0) [-3.4E+038|3.4E+038] "kVArh" Vector__XXX

BO_ 659 RC_SDM120M_15_4: 8 Vector__XXX
 SG_ ImportReactEnrgy_kVArh : 32|32@1- (1,0) [-3.4E+038|3.4E+038] "kVArh" Vector__XXX
 SG_ ExportActEnrgy_kWh : 0|32@1- (1,0) [-3.4E+038|3.4E+038] "kWh" Vector__XXX

BO_ 658 RC_SDM120M_15_3: 8 Vector__XXX
 SG_ ImportActEnrgy_kWh : 32|32@1- (1,0) [-3.4E+038|3.4E+038] "kWh" Vector__XXX
 SG_ Frequency_Hz : 0|32@1- (1,0) [-3.4E+038|3.4E+038] "Hz" Vector__XXX

BO_ 657 RC_SDM120M_15_2: 8 Vector__XXX
 SG_ PwrFctr : 32|32@1- (1,0) [-3.4E+038|3.4E+038] "" Vector__XXX
 SG_ ReactPwr_VAr : 0|32@1- (1,0) [-3.4E+038|3.4E+038] "VAr" Vector__XXX

BO_ 656 RC_SDM120M_15_1: 8 Vector__XXX
 SG_ AprntPwr_VA : 32|32@1- (1,0) [-3.4E+038|3.4E+038] "VA" Vector__XXX
 SG_ ActivePwr_W : 0|32@1- (1,0) [-3.4E+038|3.4E+038] "W" Vector__XXX

BO_ 655 RC_SDM120M_15_0: 8 RoomController
 SG_ Current_A : 32|32@1- (1,0) [-3.4E+038|3.4E+038] "A" Vector__XXX
 SG_ Voltage_V : 0|32@1- (1,0) [-3.4E+038|3.4E+038] "V" Vector__XXX

BO_ 676 RC_SDM120M_16_10: 8 Vector__XXX
 SG_ TotalReactEnrgy_kVArh : 0|32@1- (1,0) [-3.4E+038|3.4E+038] "kVArh" Vector__XXX

BO_ 675 RC_SDM120M_16_9: 8 Vector__XXX
 SG_ TotalActvEnergy_kWh : 32|32@1- (1,0) [-3.4E+038|3.4E+038] "kWh" Vector__XXX
 SG_ MaxCurrDmnd_A : 0|32@1- (1,0) [-3.4E+038|3.4E+038] "A" Vector__XXX

BO_ 674 RC_SDM120M_16_8: 8 Vector__XXX
 SG_ CurrDmnd_A : 32|32@1- (1,0) [-3.4E+038|3.4E+038] "A" Vector__XXX
 SG_ MaxExportSysPwrDmnd_W : 0|32@1- (1,0) [-3.4E+038|3.4E+038] "W" Vector__XXX

BO_ 673 RC_SDM120M_16_7: 8 Vector__XXX
 SG_ ExportSysPwrDmnd_W : 32|32@1- (1,0) [-3.4E+038|3.4E+038] "W" Vector__XXX
 SG_ MaxImportSysPwrDmnd_W : 0|32@1- (1,0) [-3.4E+038|3.4E+038] "W" Vector__XXX

BO_ 672 RC_SDM120M_16_6: 8 Vector__XXX
 SG_ ImportSysPwrDmnd_W : 32|32@1- (1,0) [-3.4E+038|3.4E+038] "W" Vector__XXX
 SG_ MaxTotalSysPwrDmnd_W : 0|32@1- (1,0) [-3.4E+038|3.4E+038] "W" Vector__XXX

BO_ 671 RC_SDM120M_16_5: 8 Vector__XXX
 SG_ TotalSysPwrDmnd_W : 32|32@1- (1,0) [-3.4E+038|3.4E+038] "W" Vector__XXX
 SG_ ExportReactEnrgy_kVArh : 0|32@1- (1,0) [-3.4E+038|3.4E+038] "kVArh" Vector__XXX

BO_ 670 RC_SDM120M_16_4: 8 Vector__XXX
 SG_ ImportReactEnrgy_kVArh : 32|32@1- (1,0) [-3.4E+038|3.4E+038] "kVArh" Vector__XXX
 SG_ ExportActEnrgy_kWh : 0|32@1- (1,0) [-3.4E+038|3.4E+038] "kWh" Vector__XXX

BO_ 669 RC_SDM120M_16_3: 8 Vector__XXX
 SG_ ImportActEnrgy_kWh : 32|32@1- (1,0) [-3.4E+038|3.4E+038] "kWh" Vector__XXX
 SG_ Frequency_Hz : 0|32@1- (1,0) [-3.4E+038|3.4E+038] "Hz" Vector__XXX

BO_ 668 RC_SDM120M_16_2: 8 Vector__XXX
 SG_ PwrFctr : 32|32@1- (1,0) [-3.4E+038|3.4E+038] "" Vector__XXX
 SG_ ReactPwr_VAr : 0|32@1- (1,0) [-3.4E+038|3.4E+038] "VAr" Vector__XXX

BO_ 667 RC_SDM120M_16_1: 8 Vector__XXX
 SG_ AprntPwr_VA : 32|32@1- (1,0) [-3.4E+038|3.4E+038] "VA" Vector__XXX
 SG_ ActivePwr_W : 0|32@1- (1,0) [-3.4E+038|3.4E+038] "W" Vector__XXX

BO_ 666 RC_SDM120M_16_0: 8 RoomController
 SG_ Current_A : 32|32@1- (1,0) [-3.4E+038|3.4E+038] "A" Vector__XXX
 SG_ Voltage_V : 0|32@1- (1,0) [-3.4E+038|3.4E+038] "V" Vector__XXX

BO_ 687 RC_SDM120M_17_10: 8 Vector__XXX
 SG_ TotalReactEnrgy_kVArh : 0|32@1- (1,0) [-3.4E+038|3.4E+038] "kVArh" Vector__XXX

BO_ 686 RC_SDM120M_17_9: 8 Vector__XXX
 SG_ TotalActvEnergy_kWh : 32|32@1- (1,0) [-3.4E+038|3.4E+038] "kWh" Vector__XXX
 SG_ MaxCurrDmnd_A : 0|32@1- (1,0) [-3.4E+038|3.4E+038] "A" Vector__XXX

BO_ 685 RC_SDM120M_17_8: 8 Vector__XXX
 SG_ CurrDmnd_A : 32|32@1- (1,0) [-3.4E+038|3.4E+038] "A" Vector__XXX
 SG_ MaxExportSysPwrDmnd_W : 0|32@1- (1,0) [-3.4E+038|3.4E+038] "W" Vector__XXX

BO_ 684 RC_SDM120M_17_7: 8 Vector__XXX
 SG_ ExportSysPwrDmnd_W : 32|32@1- (1,0) [-3.4E+038|3.4E+038] "W" Vector__XXX
 SG_ MaxImportSysPwrDmnd_W : 0|32@1- (1,0) [-3.4E+038|3.4E+038] "W" Vector__XXX

BO_ 683 RC_SDM120M_17_6: 8 Vector__XXX
 SG_ ImportSysPwrDmnd_W : 32|32@1- (1,0) [-3.4E+038|3.4E+038] "W" Vector__XXX
 SG_ MaxTotalSysPwrDmnd_W : 0|32@1- (1,0) [-3.4E+038|3.4E+038] "W" Vector__XXX

BO_ 682 RC_SDM120M_17_5: 8 Vector__XXX
 SG_ TotalSysPwrDmnd_W : 32|32@1- (1,0) [-3.4E+038|3.4E+038] "W" Vector__XXX
 SG_ ExportReactEnrgy_kVArh : 0|32@1- (1,0) [-3.4E+038|3.4E+038] "kVArh" Vector__XXX

BO_ 681 RC_SDM120M_17_4: 8 Vector__XXX
 SG_ ImportReactEnrgy_kVArh : 32|32@1- (1,0) [-3.4E+038|3.4E+038] "kVArh" Vector__XXX
 SG_ ExportActEnrgy_kWh : 0|32@1- (1,0) [-3.4E+038|3.4E+038] "kWh" Vector__XXX

BO_ 680 RC_SDM120M_17_3: 8 Vector__XXX
 SG_ ImportActEnrgy_kWh : 32|32@1- (1,0) [-3.4E+038|3.4E+038] "kWh" Vector__XXX
 SG_ Frequency_Hz : 0|32@1- (1,0) [-3.4E+038|3.4E+038] "Hz" Vector__XXX

BO_ 679 RC_SDM120M_17_2: 8 Vector__XXX
 SG_ PwrFctr : 32|32@1- (1,0) [-3.4E+038|3.4E+038] "" Vector__XXX
 SG_ ReactPwr_VAr : 0|32@1- (1,0) [-3.4E+038|3.4E+038] "VAr" Vector__XXX

BO_ 678 RC_SDM120M_17_1: 8 Vector__XXX
 SG_ AprntPwr_VA : 32|32@1- (1,0) [-3.4E+038|3.4E+038] "VA" Vector__XXX
 SG_ ActivePwr_W : 0|32@1- (1,0) [-3.4E+038|3.4E+038] "W" Vector__XXX

BO_ 677 RC_SDM120M_17_0: 8 RoomController
 SG_ Current_A : 32|32@1- (1,0) [-3.4E+038|3.4E+038] "A" Vector__XXX
 SG_ Voltage_V : 0|32@1- (1,0) [-3.4E+038|3.4E+038] "V" Vector__XXX

BO_ 698 RC_SDM120M_18_10: 8 Vector__XXX
 SG_ TotalReactEnrgy_kVArh : 0|32@1- (1,0) [-3.4E+038|3.4E+038] "kVArh" Vector__XXX

BO_ 697 RC_SDM120M_18_9: 8 Vector__XXX
 SG_ TotalActvEnergy_kWh : 32|32@1- (1,0) [-3.4E+038|3.4E+038] "kWh" Vector__XXX
 SG_ MaxCurrDmnd_A : 0|32@1- (1,0) [-3.4E+038|3.4E+038] "A" Vector__XXX

BO_ 696 RC_SDM120M_18_8: 8 Vector__XXX
 SG_ CurrDmnd_A : 32|32@1- (1,0) [-3.4E+038|3.4E+038] "A" Vector__XXX
 SG_ MaxExportSysPwrDmnd_W : 0|32@1- (1,0) [-3.4E+038|3.4E+038] "W" Vector__XXX

BO_ 695 RC_SDM120M_18_7: 8 Vector__XXX
 SG_ ExportSysPwrDmnd_W : 32|32@1- (1,0) [-3.4E+038|3.4E+038] "W" Vector__XXX
 SG_ MaxImportSysPwrDmnd_W : 0|32@1- (1,0) [-3.4E+038|3.4E+038] "W" Vector__XXX

BO_ 694 RC_SDM120M_18_6: 8 Vector__XXX
 SG_ ImportSysPwrDmnd_W : 32|32@1- (1,0) [-3.4E+038|3.4E+038] "W" Vector__XXX
 SG_ MaxTotalSysPwrDmnd_W : 0|32@1- (1,0) [-3.4E+038|3.4E+038] "W" Vector__XXX

BO_ 693 RC_SDM120M_18_5: 8 Vector__XXX
 SG_ TotalSysPwrDmnd_W : 32|32@1- (1,0) [-3.4E+038|3.4E+038] "W" Vector__XXX
 SG_ ExportReactEnrgy_kVArh : 0|32@1- (1,0) [-3.4E+038|3.4E+038] "kVArh" Vector__XXX

BO_ 692 RC_SDM120M_18_4: 8 Vector__XXX
 SG_ ImportReactEnrgy_kVArh : 32|32@1- (1,0) [-3.4E+038|3.4E+038] "kVArh" Vector__XXX
 SG_ ExportActEnrgy_kWh : 0|32@1- (1,0) [-3.4E+038|3.4E+038] "kWh" Vector__XXX

BO_ 691 RC_SDM120M_18_3: 8 Vector__XXX
 SG_ ImportActEnrgy_kWh : 32|32@1- (1,0) [-3.4E+038|3.4E+038] "kWh" Vector__XXX
 SG_ Frequency_Hz : 0|32@1- (1,0) [-3.4E+038|3.4E+038] "Hz" Vector__XXX

BO_ 690 RC_SDM120M_18_2: 8 Vector__XXX
 SG_ PwrFctr : 32|32@1- (1,0) [-3.4E+038|3.4E+038] "" Vector__XXX
 SG_ ReactPwr_VAr : 0|32@1- (1,0) [-3.4E+038|3.4E+038] "VAr" Vector__XXX

BO_ 689 RC_SDM120M_18_1: 8 Vector__XXX
 SG_ AprntPwr_VA : 32|32@1- (1,0) [-3.4E+038|3.4E+038] "VA" Vector__XXX
 SG_ ActivePwr_W : 0|32@1- (1,0) [-3.4E+038|3.4E+038] "W" Vector__XXX

BO_ 688 RC_SDM120M_18_0: 8 RoomController
 SG_ Current_A : 32|32@1- (1,0) [-3.4E+038|3.4E+038] "A" Vector__XXX
 SG_ Voltage_V : 0|32@1- (1,0) [-3.4E+038|3.4E+038] "V" Vector__XXX

BO_ 709 RC_SDM120M_19_10: 8 Vector__XXX
 SG_ TotalReactEnrgy_kVArh : 0|32@1- (1,0) [-3.4E+038|3.4E+038] "kVArh" Vector__XXX

BO_ 708 RC_SDM120M_19_9: 8 Vector__XXX
 SG_ TotalActvEnergy_kWh : 32|32@1- (1,0) [-3.4E+038|3.4E+038] "kWh" Vector__XXX
 SG_ MaxCurrDmnd_A : 0|32@1- (1,0) [-3.4E+038|3.4E+038] "A" Vector__XXX

BO_ 707 RC_SDM120M_19_8: 8 Vector__XXX
 SG_ CurrDmnd_A : 32|32@1- (1,0) [-3.4E+038|3.4E+038] "A" Vector__XXX
 SG_ MaxExportSysPwrDmnd_W : 0|32@1- (1,0) [-3.4E+038|3.4E+038] "W" Vector__XXX

BO_ 706 RC_SDM120M_19_7: 8 Vector__XXX
 SG_ ExportSysPwrDmnd_W : 32|32@1- (1,0) [-3.4E+038|3.4E+038] "W" Vector__XXX
 SG_ MaxImportSysPwrDmnd_W : 0|32@1- (1,0) [-3.4E+038|3.4E+038] "W" Vector__XXX

BO_ 705 RC_SDM120M_19_6: 8 Vector__XXX
 SG_ ImportSysPwrDmnd_W : 32|32@1- (1,0) [-3.4E+038|3.4E+038] "W" Vector__XXX
 SG_ MaxTotalSysPwrDmnd_W : 0|32@1- (1,0) [-3.4E+038|3.4E+038] "W" Vector__XXX

BO_ 704 RC_SDM120M_19_5: 8 Vector__XXX
 SG_ TotalSysPwrDmnd_W : 32|32@1- (1,0) [-3.4E+038|3.4E+038] "W" Vector__XXX
 SG_ ExportReactEnrgy_kVArh : 0|32@1- (1,0) [-3.4E+038|3.4E+038] "kVArh" Vector__XXX

BO_ 703 RC_SDM120M_19_4: 8 Vector__XXX
 SG_ ImportReactEnrgy_kVArh : 32|32@1- (1,0) [-3.4E+038|3.4E+038] "kVArh" Vector__XXX
 SG_ ExportActEnrgy_kWh : 0|32@1- (1,0) [-3.4E+038|3.4E+038] "kWh" Vector__XXX

BO_ 702 RC_SDM120M_19_3: 8 Vector__XXX
 SG_ ImportActEnrgy_kWh : 32|32@1- (1,0) [-3.4E+038|3.4E+038] "kWh" Vector__XXX
 SG_ Frequency_Hz : 0|32@1- (1,0) [-3.4E+038|3.4E+038] "Hz" Vector__XXX

BO_ 701 RC_SDM120M_19_2: 8 Vector__XXX
 SG_ PwrFctr : 32|32@1- (1,0) [-3.4E+038|3.4E+038] "" Vector__XXX
 SG_ ReactPwr_VAr : 0|32@1- (1,0) [-3.4E+038|3.4E+038] "VAr" Vector__XXX

BO_ 700 RC_SDM120M_19_1: 8 Vector__XXX
 SG_ AprntPwr_VA : 32|32@1- (1,0) [-3.4E+038|3.4E+038] "VA" Vector__XXX
 SG_ ActivePwr_W : 0|32@1- (1,0) [-3.4E+038|3.4E+038] "W" Vector__XXX

BO_ 699 RC_SDM120M_19_0: 8 RoomController
 SG_ Current_A : 32|32@1- (1,0) [-3.4E+038|3.4E+038] "A" Vector__XXX
 SG_ Voltage_V : 0|32@1- (1,0) [-3.4E+038|3.4E+038] "V" Vector__XXX

BO_ 720 RC_SDM120M_20_10: 8 Vector__XXX
 SG_ TotalReactEnrgy_kVArh : 0|32@1- (1,0) [-3.4E+038|3.4E+038] "kVArh" Vector__XXX

BO_ 719 RC_SDM120M_20_9: 8 Vector__XXX
 SG_ TotalActvEnergy_kWh : 32|32@1- (1,0) [-3.4E+038|3.4E+038] "kWh" Vector__XXX
 SG_ MaxCurrDmnd_A : 0|32@1- (1,0) [-3.4E+038|3.4E+038] "A" Vector__XXX

BO_ 718 RC_SDM120M_20_8: 8 Vector__XXX
 SG_ CurrDmnd_A : 32|32@1- (1,0) [-3.4E+038|3.4E+038] "A" Vector__XXX
 SG_ MaxExportSysPwrDmnd_W : 0|32@1- (1,0) [-3.4E+038|3.4E+038] "W" Vector__XXX

BO_ 717 RC_SDM120M_20_7: 8 Vector__XXX
 SG_ ExportSysPwrDmnd_W : 32|32@1- (1,0) [-3.4E+038|3.4E+038] "W" Vector__XXX
 SG_ MaxImportSysPwrDmnd_W : 0|32@1- (1,0) [-3.4E+038|3.4E+038] "W" Vector__XXX

BO_ 716 RC_SDM120M_20_6: 8 Vector__XXX
 SG_ ImportSysPwrDmnd_W : 32|32@1- (1,0) [-3.4E+038|3.4E+038] "W" Vector__XXX
 SG_ MaxTotalSysPwrDmnd_W : 0|32@1- (1,0) [-3.4E+038|3.4E+038] "W" Vector__XXX

BO_ 715 RC_SDM120M_20_5: 8 Vector__XXX
 SG_ TotalSysPwrDmnd_W : 32|32@1- (1,0) [-3.4E+038|3.4E+038] "W" Vector__XXX
 SG_ ExportReactEnrgy_kVArh : 0|32@1- (1,0) [-3.4E+038|3.4E+038] "kVArh" Vector__XXX

BO_ 714 RC_SDM120M_20_4: 8 Vector__XXX
 SG_ ImportReactEnrgy_kVArh : 32|32@1- (1,0) [-3.4E+038|3.4E+038] "kVArh" Vector__XXX
 SG_ ExportActEnrgy_kWh : 0|32@1- (1,0) [-3.4E+038|3.4E+038] "kWh" Vector__XXX

BO_ 713 RC_SDM120M_20_3: 8 Vector__XXX
 SG_ ImportActEnrgy_kWh : 32|32@1- (1,0) [-3.4E+038|3.4E+038] "kWh" Vector__XXX
 SG_ Frequency_Hz : 0|32@1- (1,0) [-3.4E+038|3.4E+038] "Hz" Vector__XXX

BO_ 712 RC_SDM120M_20_2: 8 Vector__XXX
 SG_ PwrFctr : 32|32@1- (1,0) [-3.4E+038|3.4E+038] "" Vector__XXX
 SG_ ReactPwr_VAr : 0|32@1- (1,0) [-3.4E+038|3.4E+038] "VAr" Vector__XXX

BO_ 711 RC_SDM120M_20_1: 8 Vector__XXX
 SG_ AprntPwr_VA : 32|32@1- (1,0) [-3.4E+038|3.4E+038] "VA" Vector__XXX
 SG_ ActivePwr_W : 0|32@1- (1,0) [-3.4E+038|3.4E+038] "W" Vector__XXX

BO_ 710 RC_SDM120M_20_0: 8 RoomController
 SG_ Current_A : 32|32@1- (1,0) [-3.4E+038|3.4E+038] "A" Vector__XXX
 SG_ Voltage_V : 0|32@1- (1,0) [-3.4E+038|3.4E+038] "V" Vector__XXX

CM_ BO_ 3221225472 "This is a message for not used signals, created by Vector CANdb++ DBC OLE DB Provider.";
CM_ BO_ 24 "Direct Memory Access Server command message";
CM_ BO_ 23 "Direct Memory Access Server command message";
CM_ BO_ 22 "Direct Memory Access Server command message";
CM_ BO_ 21 "Direct Memory Access Server command message";
CM_ BO_ 20 "Direct Memory Access Server command message";
CM_ BO_ 19 "Direct Memory Access Server command message";
CM_ BO_ 18 "Direct Memory Access Server command message";
CM_ BO_ 17 "Direct Memory Access Server command message";
CM_ BO_ 32 "Direct Memory Access Server response message";
CM_ BO_ 16 "Direct Memory Access Server command message";
BA_DEF_ BO_  "CANFD_BRS" ENUM  "0","1";
BA_DEF_  "DBName" STRING ;
BA_DEF_  "BusType" STRING ;
BA_DEF_ BO_  "VFrameFormat" ENUM  "StandardCAN","ExtendedCAN","reserved","reserved","reserved","reserved","reserved","reserved","reserved","reserved","reserved","reserved","reserved","reserved","StandardCAN_FD","ExtendedCAN_FD";
BA_DEF_DEF_  "CANFD_BRS" "1";
BA_DEF_DEF_  "DBName" "";
BA_DEF_DEF_  "BusType" "";
BA_DEF_DEF_  "VFrameFormat" "StandardCAN";
BA_ "BusType" "CAN FD";
BA_ "DBName" "CAN_database";
VAL_ 3221225472 DMAS_var_type 8 "DMAS_TES" 7 "DMAS_TBS" 6 "DMAS_TF32S" 5 "DMAS_TS32" 4 "DMAS_TS16" 3 "DMAS_TS8" 2 "DMAS_TU32" 1 "DMAS_TU16" 0 "DMAS_TU8" ;
VAL_ 24 DMAS_stream_time 5 "stream 5000ms" 4 "stream 1000ms" 3 "stream 500ms" 2 "stream 100ms" 1 "stream 50ms" 0 "stream 10ms" ;
VAL_ 24 DMAS_cmd_mode 4 "DMAS_MODE_STOPOVERWRITE" 3 "DMAS_MODE_OVERWRITE" 2 "DMAS_MODE_WRITE" 1 "DMAS_MODE_STOP_READ" 0 "DMAS_MODE_READ_REQ" ;
VAL_ 23 DMAS_stream_time 5 "stream 5000ms" 4 "stream 1000ms" 3 "stream 500ms" 2 "stream 100ms" 1 "stream 50ms" 0 "stream 10ms" ;
VAL_ 23 DMAS_cmd_mode 4 "DMAS_MODE_STOPOVERWRITE" 3 "DMAS_MODE_OVERWRITE" 2 "DMAS_MODE_WRITE" 1 "DMAS_MODE_STOP_READ" 0 "DMAS_MODE_READ_REQ" ;
VAL_ 22 DMAS_stream_time 5 "stream 5000ms" 4 "stream 1000ms" 3 "stream 500ms" 2 "stream 100ms" 1 "stream 50ms" 0 "stream 10ms" ;
VAL_ 22 DMAS_cmd_mode 4 "DMAS_MODE_STOPOVERWRITE" 3 "DMAS_MODE_OVERWRITE" 2 "DMAS_MODE_WRITE" 1 "DMAS_MODE_STOP_READ" 0 "DMAS_MODE_READ_REQ" ;
VAL_ 21 DMAS_stream_time 5 "stream 5000ms" 4 "stream 1000ms" 3 "stream 500ms" 2 "stream 100ms" 1 "stream 50ms" 0 "stream 10ms" ;
VAL_ 21 DMAS_cmd_mode 4 "DMAS_MODE_STOPOVERWRITE" 3 "DMAS_MODE_OVERWRITE" 2 "DMAS_MODE_WRITE" 1 "DMAS_MODE_STOP_READ" 0 "DMAS_MODE_READ_REQ" ;
VAL_ 20 DMAS_stream_time 5 "stream 5000ms" 4 "stream 1000ms" 3 "stream 500ms" 2 "stream 100ms" 1 "stream 50ms" 0 "stream 10ms" ;
VAL_ 20 DMAS_cmd_mode 4 "DMAS_MODE_STOPOVERWRITE" 3 "DMAS_MODE_OVERWRITE" 2 "DMAS_MODE_WRITE" 1 "DMAS_MODE_STOP_READ" 0 "DMAS_MODE_READ_REQ" ;
VAL_ 19 DMAS_stream_time 5 "stream 5000ms" 4 "stream 1000ms" 3 "stream 500ms" 2 "stream 100ms" 1 "stream 50ms" 0 "stream 10ms" ;
VAL_ 19 DMAS_cmd_mode 4 "DMAS_MODE_STOPOVERWRITE" 3 "DMAS_MODE_OVERWRITE" 2 "DMAS_MODE_WRITE" 1 "DMAS_MODE_STOP_READ" 0 "DMAS_MODE_READ_REQ" ;
VAL_ 18 DMAS_stream_time 5 "stream 5000ms" 4 "stream 1000ms" 3 "stream 500ms" 2 "stream 100ms" 1 "stream 50ms" 0 "stream 10ms" ;
VAL_ 18 DMAS_cmd_mode 4 "DMAS_MODE_STOPOVERWRITE" 3 "DMAS_MODE_OVERWRITE" 2 "DMAS_MODE_WRITE" 1 "DMAS_MODE_STOP_READ" 0 "DMAS_MODE_READ_REQ" ;
VAL_ 17 DMAS_stream_time 5 "stream 5000ms" 4 "stream 1000ms" 3 "stream 500ms" 2 "stream 100ms" 1 "stream 50ms" 0 "stream 10ms" ;
VAL_ 17 DMAS_cmd_mode 4 "DMAS_MODE_STOPOVERWRITE" 3 "DMAS_MODE_OVERWRITE" 2 "DMAS_MODE_WRITE" 1 "DMAS_MODE_STOP_READ" 0 "DMAS_MODE_READ_REQ" ;
VAL_ 32 DMAS_var_type 8 "DMAS_TES" 7 "DMAS_TBS" 6 "DMAS_TF32S" 5 "DMAS_TS32" 4 "DMAS_TS16" 3 "DMAS_TS8" 2 "DMAS_TU32" 1 "DMAS_TU16" 0 "DMAS_TU8" ;
VAL_ 32 DMAS_stream_time 5 "stream 5000ms" 4 "stream 1000ms" 3 "stream 500ms" 2 "stream 100ms" 1 "stream 50ms" 0 "stream 10ms" ;
VAL_ 16 DMAS_stream_time 5 "stream 5000ms" 4 "stream 1000ms" 3 "stream 500ms" 2 "stream 100ms" 1 "stream 50ms" 0 "stream 10ms" ;
VAL_ 16 DMAS_cmd_mode 4 "DMAS_MODE_STOPOVERWRITE" 3 "DMAS_MODE_OVERWRITE" 2 "DMAS_MODE_WRITE" 1 "DMAS_MODE_STOP_READ" 0 "DMAS_MODE_READ_REQ" ;
SIG_VALTYPE_ 48 Lux : 1;
SIG_VALTYPE_ 22 DMAS_payload_tF32 : 1;
SIG_VALTYPE_ 511 TotalReactEnrgy_kVArh : 1;
SIG_VALTYPE_ 510 TotalActvEnergy_kWh : 1;
SIG_VALTYPE_ 510 MaxCurrDmnd_A : 1;
SIG_VALTYPE_ 509 CurrDmnd_A : 1;
SIG_VALTYPE_ 509 MaxExportSysPwrDmnd_W : 1;
SIG_VALTYPE_ 508 ExportSysPwrDmnd_W : 1;
SIG_VALTYPE_ 508 MaxImportSysPwrDmnd_W : 1;
SIG_VALTYPE_ 507 ImportSysPwrDmnd_W : 1;
SIG_VALTYPE_ 507 MaxTotalSysPwrDmnd_W : 1;
SIG_VALTYPE_ 506 TotalSysPwrDmnd_W : 1;
SIG_VALTYPE_ 506 ExportReactEnrgy_kVArh : 1;
SIG_VALTYPE_ 505 ImportReactEnrgy_kVArh : 1;
SIG_VALTYPE_ 505 ExportActEnrgy_kWh : 1;
SIG_VALTYPE_ 504 ImportActEnrgy_kWh : 1;
SIG_VALTYPE_ 504 Frequency_Hz : 1;
SIG_VALTYPE_ 503 PwrFctr : 1;
SIG_VALTYPE_ 503 ReactPwr_VAr : 1;
SIG_VALTYPE_ 502 ActivePwr_W : 1;
SIG_VALTYPE_ 502 AprntPwr_VA : 1;
SIG_VALTYPE_ 501 Current_A : 1;
SIG_VALTYPE_ 501 Voltage_V : 1;
SIG_VALTYPE_ 522 TotalReactEnrgy_kVArh : 1;
SIG_VALTYPE_ 521 TotalActvEnergy_kWh : 1;
SIG_VALTYPE_ 521 MaxCurrDmnd_A : 1;
SIG_VALTYPE_ 520 CurrDmnd_A : 1;
SIG_VALTYPE_ 520 MaxExportSysPwrDmnd_W : 1;
SIG_VALTYPE_ 519 ExportSysPwrDmnd_W : 1;
SIG_VALTYPE_ 519 MaxImportSysPwrDmnd_W : 1;
SIG_VALTYPE_ 518 ImportSysPwrDmnd_W : 1;
SIG_VALTYPE_ 518 MaxTotalSysPwrDmnd_W : 1;
SIG_VALTYPE_ 517 TotalSysPwrDmnd_W : 1;
SIG_VALTYPE_ 517 ExportReactEnrgy_kVArh : 1;
SIG_VALTYPE_ 516 ImportReactEnrgy_kVArh : 1;
SIG_VALTYPE_ 516 ExportActEnrgy_kWh : 1;
SIG_VALTYPE_ 515 ImportActEnrgy_kWh : 1;
SIG_VALTYPE_ 515 Frequency_Hz : 1;
SIG_VALTYPE_ 514 PwrFctr : 1;
SIG_VALTYPE_ 514 ReactPwr_VAr : 1;
SIG_VALTYPE_ 513 ActivePwr_W : 1;
SIG_VALTYPE_ 513 AprntPwr_VA : 1;
SIG_VALTYPE_ 512 Current_A : 1;
SIG_VALTYPE_ 512 Voltage_V : 1;
SIG_VALTYPE_ 533 TotalReactEnrgy_kVArh : 1;
SIG_VALTYPE_ 532 TotalActvEnergy_kWh : 1;
SIG_VALTYPE_ 532 MaxCurrDmnd_A : 1;
SIG_VALTYPE_ 531 CurrDmnd_A : 1;
SIG_VALTYPE_ 531 MaxExportSysPwrDmnd_W : 1;
SIG_VALTYPE_ 530 ExportSysPwrDmnd_W : 1;
SIG_VALTYPE_ 530 MaxImportSysPwrDmnd_W : 1;
SIG_VALTYPE_ 529 ImportSysPwrDmnd_W : 1;
SIG_VALTYPE_ 529 MaxTotalSysPwrDmnd_W : 1;
SIG_VALTYPE_ 528 TotalSysPwrDmnd_W : 1;
SIG_VALTYPE_ 528 ExportReactEnrgy_kVArh : 1;
SIG_VALTYPE_ 527 ImportReactEnrgy_kVArh : 1;
SIG_VALTYPE_ 527 ExportActEnrgy_kWh : 1;
SIG_VALTYPE_ 526 ImportActEnrgy_kWh : 1;
SIG_VALTYPE_ 526 Frequency_Hz : 1;
SIG_VALTYPE_ 525 PwrFctr : 1;
SIG_VALTYPE_ 525 ReactPwr_VAr : 1;
SIG_VALTYPE_ 524 ActivePwr_W : 1;
SIG_VALTYPE_ 524 AprntPwr_VA : 1;
SIG_VALTYPE_ 523 Current_A : 1;
SIG_VALTYPE_ 523 Voltage_V : 1;
SIG_VALTYPE_ 544 TotalReactEnrgy_kVArh : 1;
SIG_VALTYPE_ 543 TotalActvEnergy_kWh : 1;
SIG_VALTYPE_ 543 MaxCurrDmnd_A : 1;
SIG_VALTYPE_ 542 CurrDmnd_A : 1;
SIG_VALTYPE_ 542 MaxExportSysPwrDmnd_W : 1;
SIG_VALTYPE_ 541 ExportSysPwrDmnd_W : 1;
SIG_VALTYPE_ 541 MaxImportSysPwrDmnd_W : 1;
SIG_VALTYPE_ 540 ImportSysPwrDmnd_W : 1;
SIG_VALTYPE_ 540 MaxTotalSysPwrDmnd_W : 1;
SIG_VALTYPE_ 539 TotalSysPwrDmnd_W : 1;
SIG_VALTYPE_ 539 ExportReactEnrgy_kVArh : 1;
SIG_VALTYPE_ 538 ImportReactEnrgy_kVArh : 1;
SIG_VALTYPE_ 538 ExportActEnrgy_kWh : 1;
SIG_VALTYPE_ 537 ImportActEnrgy_kWh : 1;
SIG_VALTYPE_ 537 Frequency_Hz : 1;
SIG_VALTYPE_ 536 PwrFctr : 1;
SIG_VALTYPE_ 536 ReactPwr_VAr : 1;
SIG_VALTYPE_ 535 ActivePwr_W : 1;
SIG_VALTYPE_ 535 AprntPwr_VA : 1;
SIG_VALTYPE_ 534 Current_A : 1;
SIG_VALTYPE_ 534 Voltage_V : 1;
SIG_VALTYPE_ 555 TotalReactEnrgy_kVArh : 1;
SIG_VALTYPE_ 554 TotalActvEnergy_kWh : 1;
SIG_VALTYPE_ 554 MaxCurrDmnd_A : 1;
SIG_VALTYPE_ 553 CurrDmnd_A : 1;
SIG_VALTYPE_ 553 MaxExportSysPwrDmnd_W : 1;
SIG_VALTYPE_ 552 ExportSysPwrDmnd_W : 1;
SIG_VALTYPE_ 552 MaxImportSysPwrDmnd_W : 1;
SIG_VALTYPE_ 551 ImportSysPwrDmnd_W : 1;
SIG_VALTYPE_ 551 MaxTotalSysPwrDmnd_W : 1;
SIG_VALTYPE_ 550 TotalSysPwrDmnd_W : 1;
SIG_VALTYPE_ 550 ExportReactEnrgy_kVArh : 1;
SIG_VALTYPE_ 549 ImportReactEnrgy_kVArh : 1;
SIG_VALTYPE_ 549 ExportActEnrgy_kWh : 1;
SIG_VALTYPE_ 548 ImportActEnrgy_kWh : 1;
SIG_VALTYPE_ 548 Frequency_Hz : 1;
SIG_VALTYPE_ 547 PwrFctr : 1;
SIG_VALTYPE_ 547 ReactPwr_VAr : 1;
SIG_VALTYPE_ 546 ActivePwr_W : 1;
SIG_VALTYPE_ 546 AprntPwr_VA : 1;
SIG_VALTYPE_ 545 Current_A : 1;
SIG_VALTYPE_ 545 Voltage_V : 1;
SIG_VALTYPE_ 566 TotalReactEnrgy_kVArh : 1;
SIG_VALTYPE_ 565 TotalActvEnergy_kWh : 1;
SIG_VALTYPE_ 565 MaxCurrDmnd_A : 1;
SIG_VALTYPE_ 564 CurrDmnd_A : 1;
SIG_VALTYPE_ 564 MaxExportSysPwrDmnd_W : 1;
SIG_VALTYPE_ 563 ExportSysPwrDmnd_W : 1;
SIG_VALTYPE_ 563 MaxImportSysPwrDmnd_W : 1;
SIG_VALTYPE_ 562 ImportSysPwrDmnd_W : 1;
SIG_VALTYPE_ 562 MaxTotalSysPwrDmnd_W : 1;
SIG_VALTYPE_ 561 TotalSysPwrDmnd_W : 1;
SIG_VALTYPE_ 561 ExportReactEnrgy_kVArh : 1;
SIG_VALTYPE_ 560 ImportReactEnrgy_kVArh : 1;
SIG_VALTYPE_ 560 ExportActEnrgy_kWh : 1;
SIG_VALTYPE_ 559 ImportActEnrgy_kWh : 1;
SIG_VALTYPE_ 559 Frequency_Hz : 1;
SIG_VALTYPE_ 558 PwrFctr : 1;
SIG_VALTYPE_ 558 ReactPwr_VAr : 1;
SIG_VALTYPE_ 557 ActivePwr_W : 1;
SIG_VALTYPE_ 557 AprntPwr_VA : 1;
SIG_VALTYPE_ 556 Current_A : 1;
SIG_VALTYPE_ 556 Voltage_V : 1;
SIG_VALTYPE_ 577 TotalReactEnrgy_kVArh : 1;
SIG_VALTYPE_ 576 TotalActvEnergy_kWh : 1;
SIG_VALTYPE_ 576 MaxCurrDmnd_A : 1;
SIG_VALTYPE_ 575 CurrDmnd_A : 1;
SIG_VALTYPE_ 575 MaxExportSysPwrDmnd_W : 1;
SIG_VALTYPE_ 574 ExportSysPwrDmnd_W : 1;
SIG_VALTYPE_ 574 MaxImportSysPwrDmnd_W : 1;
SIG_VALTYPE_ 573 ImportSysPwrDmnd_W : 1;
SIG_VALTYPE_ 573 MaxTotalSysPwrDmnd_W : 1;
SIG_VALTYPE_ 572 TotalSysPwrDmnd_W : 1;
SIG_VALTYPE_ 572 ExportReactEnrgy_kVArh : 1;
SIG_VALTYPE_ 571 ImportReactEnrgy_kVArh : 1;
SIG_VALTYPE_ 571 ExportActEnrgy_kWh : 1;
SIG_VALTYPE_ 570 ImportActEnrgy_kWh : 1;
SIG_VALTYPE_ 570 Frequency_Hz : 1;
SIG_VALTYPE_ 569 PwrFctr : 1;
SIG_VALTYPE_ 569 ReactPwr_VAr : 1;
SIG_VALTYPE_ 568 ActivePwr_W : 1;
SIG_VALTYPE_ 568 AprntPwr_VA : 1;
SIG_VALTYPE_ 567 Current_A : 1;
SIG_VALTYPE_ 567 Voltage_V : 1;
SIG_VALTYPE_ 588 TotalReactEnrgy_kVArh : 1;
SIG_VALTYPE_ 587 TotalActvEnergy_kWh : 1;
SIG_VALTYPE_ 587 MaxCurrDmnd_A : 1;
SIG_VALTYPE_ 586 CurrDmnd_A : 1;
SIG_VALTYPE_ 586 MaxExportSysPwrDmnd_W : 1;
SIG_VALTYPE_ 585 ExportSysPwrDmnd_W : 1;
SIG_VALTYPE_ 585 MaxImportSysPwrDmnd_W : 1;
SIG_VALTYPE_ 584 ImportSysPwrDmnd_W : 1;
SIG_VALTYPE_ 584 MaxTotalSysPwrDmnd_W : 1;
SIG_VALTYPE_ 583 TotalSysPwrDmnd_W : 1;
SIG_VALTYPE_ 583 ExportReactEnrgy_kVArh : 1;
SIG_VALTYPE_ 582 ImportReactEnrgy_kVArh : 1;
SIG_VALTYPE_ 582 ExportActEnrgy_kWh : 1;
SIG_VALTYPE_ 581 ImportActEnrgy_kWh : 1;
SIG_VALTYPE_ 581 Frequency_Hz : 1;
SIG_VALTYPE_ 580 PwrFctr : 1;
SIG_VALTYPE_ 580 ReactPwr_VAr : 1;
SIG_VALTYPE_ 579 ActivePwr_W : 1;
SIG_VALTYPE_ 579 AprntPwr_VA : 1;
SIG_VALTYPE_ 578 Current_A : 1;
SIG_VALTYPE_ 578 Voltage_V : 1;
SIG_VALTYPE_ 599 TotalReactEnrgy_kVArh : 1;
SIG_VALTYPE_ 598 TotalActvEnergy_kWh : 1;
SIG_VALTYPE_ 598 MaxCurrDmnd_A : 1;
SIG_VALTYPE_ 597 CurrDmnd_A : 1;
SIG_VALTYPE_ 597 MaxExportSysPwrDmnd_W : 1;
SIG_VALTYPE_ 596 ExportSysPwrDmnd_W : 1;
SIG_VALTYPE_ 596 MaxImportSysPwrDmnd_W : 1;
SIG_VALTYPE_ 595 ImportSysPwrDmnd_W : 1;
SIG_VALTYPE_ 595 MaxTotalSysPwrDmnd_W : 1;
SIG_VALTYPE_ 594 TotalSysPwrDmnd_W : 1;
SIG_VALTYPE_ 594 ExportReactEnrgy_kVArh : 1;
SIG_VALTYPE_ 593 ImportReactEnrgy_kVArh : 1;
SIG_VALTYPE_ 593 ExportActEnrgy_kWh : 1;
SIG_VALTYPE_ 592 ImportActEnrgy_kWh : 1;
SIG_VALTYPE_ 592 Frequency_Hz : 1;
SIG_VALTYPE_ 591 PwrFctr : 1;
SIG_VALTYPE_ 591 ReactPwr_VAr : 1;
SIG_VALTYPE_ 590 ActivePwr_W : 1;
SIG_VALTYPE_ 590 AprntPwr_VA : 1;
SIG_VALTYPE_ 589 Current_A : 1;
SIG_VALTYPE_ 589 Voltage_V : 1;
SIG_VALTYPE_ 610 TotalReactEnrgy_kVArh : 1;
SIG_VALTYPE_ 609 TotalActvEnergy_kWh : 1;
SIG_VALTYPE_ 609 MaxCurrDmnd_A : 1;
SIG_VALTYPE_ 608 CurrDmnd_A : 1;
SIG_VALTYPE_ 608 MaxExportSysPwrDmnd_W : 1;
SIG_VALTYPE_ 607 ExportSysPwrDmnd_W : 1;
SIG_VALTYPE_ 607 MaxImportSysPwrDmnd_W : 1;
SIG_VALTYPE_ 606 ImportSysPwrDmnd_W : 1;
SIG_VALTYPE_ 606 MaxTotalSysPwrDmnd_W : 1;
SIG_VALTYPE_ 605 TotalSysPwrDmnd_W : 1;
SIG_VALTYPE_ 605 ExportReactEnrgy_kVArh : 1;
SIG_VALTYPE_ 604 ImportReactEnrgy_kVArh : 1;
SIG_VALTYPE_ 604 ExportActEnrgy_kWh : 1;
SIG_VALTYPE_ 603 ImportActEnrgy_kWh : 1;
SIG_VALTYPE_ 603 Frequency_Hz : 1;
SIG_VALTYPE_ 602 PwrFctr : 1;
SIG_VALTYPE_ 602 ReactPwr_VAr : 1;
SIG_VALTYPE_ 601 ActivePwr_W : 1;
SIG_VALTYPE_ 601 AprntPwr_VA : 1;
SIG_VALTYPE_ 600 Current_A : 1;
SIG_VALTYPE_ 600 Voltage_V : 1;
SIG_VALTYPE_ 621 TotalReactEnrgy_kVArh : 1;
SIG_VALTYPE_ 620 TotalActvEnergy_kWh : 1;
SIG_VALTYPE_ 620 MaxCurrDmnd_A : 1;
SIG_VALTYPE_ 619 CurrDmnd_A : 1;
SIG_VALTYPE_ 619 MaxExportSysPwrDmnd_W : 1;
SIG_VALTYPE_ 618 ExportSysPwrDmnd_W : 1;
SIG_VALTYPE_ 618 MaxImportSysPwrDmnd_W : 1;
SIG_VALTYPE_ 617 ImportSysPwrDmnd_W : 1;
SIG_VALTYPE_ 617 MaxTotalSysPwrDmnd_W : 1;
SIG_VALTYPE_ 616 TotalSysPwrDmnd_W : 1;
SIG_VALTYPE_ 616 ExportReactEnrgy_kVArh : 1;
SIG_VALTYPE_ 615 ImportReactEnrgy_kVArh : 1;
SIG_VALTYPE_ 615 ExportActEnrgy_kWh : 1;
SIG_VALTYPE_ 614 ImportActEnrgy_kWh : 1;
SIG_VALTYPE_ 614 Frequency_Hz : 1;
SIG_VALTYPE_ 613 PwrFctr : 1;
SIG_VALTYPE_ 613 ReactPwr_VAr : 1;
SIG_VALTYPE_ 612 ActivePwr_W : 1;
SIG_VALTYPE_ 612 AprntPwr_VA : 1;
SIG_VALTYPE_ 611 Current_A : 1;
SIG_VALTYPE_ 611 Voltage_V : 1;
SIG_VALTYPE_ 632 TotalReactEnrgy_kVArh : 1;
SIG_VALTYPE_ 631 TotalActvEnergy_kWh : 1;
SIG_VALTYPE_ 631 MaxCurrDmnd_A : 1;
SIG_VALTYPE_ 630 CurrDmnd_A : 1;
SIG_VALTYPE_ 630 MaxExportSysPwrDmnd_W : 1;
SIG_VALTYPE_ 629 ExportSysPwrDmnd_W : 1;
SIG_VALTYPE_ 629 MaxImportSysPwrDmnd_W : 1;
SIG_VALTYPE_ 628 ImportSysPwrDmnd_W : 1;
SIG_VALTYPE_ 628 MaxTotalSysPwrDmnd_W : 1;
SIG_VALTYPE_ 627 TotalSysPwrDmnd_W : 1;
SIG_VALTYPE_ 627 ExportReactEnrgy_kVArh : 1;
SIG_VALTYPE_ 626 ImportReactEnrgy_kVArh : 1;
SIG_VALTYPE_ 626 ExportActEnrgy_kWh : 1;
SIG_VALTYPE_ 625 ImportActEnrgy_kWh : 1;
SIG_VALTYPE_ 625 Frequency_Hz : 1;
SIG_VALTYPE_ 624 PwrFctr : 1;
SIG_VALTYPE_ 624 ReactPwr_VAr : 1;
SIG_VALTYPE_ 623 ActivePwr_W : 1;
SIG_VALTYPE_ 623 AprntPwr_VA : 1;
SIG_VALTYPE_ 622 Current_A : 1;
SIG_VALTYPE_ 622 Voltage_V : 1;
SIG_VALTYPE_ 643 TotalReactEnrgy_kVArh : 1;
SIG_VALTYPE_ 642 TotalActvEnergy_kWh : 1;
SIG_VALTYPE_ 642 MaxCurrDmnd_A : 1;
SIG_VALTYPE_ 641 CurrDmnd_A : 1;
SIG_VALTYPE_ 641 MaxExportSysPwrDmnd_W : 1;
SIG_VALTYPE_ 640 ExportSysPwrDmnd_W : 1;
SIG_VALTYPE_ 640 MaxImportSysPwrDmnd_W : 1;
SIG_VALTYPE_ 639 ImportSysPwrDmnd_W : 1;
SIG_VALTYPE_ 639 MaxTotalSysPwrDmnd_W : 1;
SIG_VALTYPE_ 638 TotalSysPwrDmnd_W : 1;
SIG_VALTYPE_ 638 ExportReactEnrgy_kVArh : 1;
SIG_VALTYPE_ 637 ImportReactEnrgy_kVArh : 1;
SIG_VALTYPE_ 637 ExportActEnrgy_kWh : 1;
SIG_VALTYPE_ 636 ImportActEnrgy_kWh : 1;
SIG_VALTYPE_ 636 Frequency_Hz : 1;
SIG_VALTYPE_ 635 PwrFctr : 1;
SIG_VALTYPE_ 635 ReactPwr_VAr : 1;
SIG_VALTYPE_ 634 ActivePwr_W : 1;
SIG_VALTYPE_ 634 AprntPwr_VA : 1;
SIG_VALTYPE_ 633 Current_A : 1;
SIG_VALTYPE_ 633 Voltage_V : 1;
SIG_VALTYPE_ 654 TotalReactEnrgy_kVArh : 1;
SIG_VALTYPE_ 653 TotalActvEnergy_kWh : 1;
SIG_VALTYPE_ 653 MaxCurrDmnd_A : 1;
SIG_VALTYPE_ 652 CurrDmnd_A : 1;
SIG_VALTYPE_ 652 MaxExportSysPwrDmnd_W : 1;
SIG_VALTYPE_ 651 ExportSysPwrDmnd_W : 1;
SIG_VALTYPE_ 651 MaxImportSysPwrDmnd_W : 1;
SIG_VALTYPE_ 650 ImportSysPwrDmnd_W : 1;
SIG_VALTYPE_ 650 MaxTotalSysPwrDmnd_W : 1;
SIG_VALTYPE_ 649 TotalSysPwrDmnd_W : 1;
SIG_VALTYPE_ 649 ExportReactEnrgy_kVArh : 1;
SIG_VALTYPE_ 648 ImportReactEnrgy_kVArh : 1;
SIG_VALTYPE_ 648 ExportActEnrgy_kWh : 1;
SIG_VALTYPE_ 647 ImportActEnrgy_kWh : 1;
SIG_VALTYPE_ 647 Frequency_Hz : 1;
SIG_VALTYPE_ 646 PwrFctr : 1;
SIG_VALTYPE_ 646 ReactPwr_VAr : 1;
SIG_VALTYPE_ 645 ActivePwr_W : 1;
SIG_VALTYPE_ 645 AprntPwr_VA : 1;
SIG_VALTYPE_ 644 Current_A : 1;
SIG_VALTYPE_ 644 Voltage_V : 1;
SIG_VALTYPE_ 665 TotalReactEnrgy_kVArh : 1;
SIG_VALTYPE_ 664 TotalActvEnergy_kWh : 1;
SIG_VALTYPE_ 664 MaxCurrDmnd_A : 1;
SIG_VALTYPE_ 663 CurrDmnd_A : 1;
SIG_VALTYPE_ 663 MaxExportSysPwrDmnd_W : 1;
SIG_VALTYPE_ 662 ExportSysPwrDmnd_W : 1;
SIG_VALTYPE_ 662 MaxImportSysPwrDmnd_W : 1;
SIG_VALTYPE_ 661 ImportSysPwrDmnd_W : 1;
SIG_VALTYPE_ 661 MaxTotalSysPwrDmnd_W : 1;
SIG_VALTYPE_ 660 TotalSysPwrDmnd_W : 1;
SIG_VALTYPE_ 660 ExportReactEnrgy_kVArh : 1;
SIG_VALTYPE_ 659 ImportReactEnrgy_kVArh : 1;
SIG_VALTYPE_ 659 ExportActEnrgy_kWh : 1;
SIG_VALTYPE_ 658 ImportActEnrgy_kWh : 1;
SIG_VALTYPE_ 658 Frequency_Hz : 1;
SIG_VALTYPE_ 657 PwrFctr : 1;
SIG_VALTYPE_ 657 ReactPwr_VAr : 1;
SIG_VALTYPE_ 656 ActivePwr_W : 1;
SIG_VALTYPE_ 656 AprntPwr_VA : 1;
SIG_VALTYPE_ 655 Current_A : 1;
SIG_VALTYPE_ 655 Voltage_V : 1;
SIG_VALTYPE_ 676 TotalReactEnrgy_kVArh : 1;
SIG_VALTYPE_ 675 TotalActvEnergy_kWh : 1;
SIG_VALTYPE_ 675 MaxCurrDmnd_A : 1;
SIG_VALTYPE_ 674 CurrDmnd_A : 1;
SIG_VALTYPE_ 674 MaxExportSysPwrDmnd_W : 1;
SIG_VALTYPE_ 673 ExportSysPwrDmnd_W : 1;
SIG_VALTYPE_ 673 MaxImportSysPwrDmnd_W : 1;
SIG_VALTYPE_ 672 ImportSysPwrDmnd_W : 1;
SIG_VALTYPE_ 672 MaxTotalSysPwrDmnd_W : 1;
SIG_VALTYPE_ 671 TotalSysPwrDmnd_W : 1;
SIG_VALTYPE_ 671 ExportReactEnrgy_kVArh : 1;
SIG_VALTYPE_ 670 ImportReactEnrgy_kVArh : 1;
SIG_VALTYPE_ 670 ExportActEnrgy_kWh : 1;
SIG_VALTYPE_ 669 ImportActEnrgy_kWh : 1;
SIG_VALTYPE_ 669 Frequency_Hz : 1;
SIG_VALTYPE_ 668 PwrFctr : 1;
SIG_VALTYPE_ 668 ReactPwr_VAr : 1;
SIG_VALTYPE_ 667 ActivePwr_W : 1;
SIG_VALTYPE_ 667 AprntPwr_VA : 1;
SIG_VALTYPE_ 666 Current_A : 1;
SIG_VALTYPE_ 666 Voltage_V : 1;
SIG_VALTYPE_ 687 TotalReactEnrgy_kVArh : 1;
SIG_VALTYPE_ 686 TotalActvEnergy_kWh : 1;
SIG_VALTYPE_ 686 MaxCurrDmnd_A : 1;
SIG_VALTYPE_ 685 CurrDmnd_A : 1;
SIG_VALTYPE_ 685 MaxExportSysPwrDmnd_W : 1;
SIG_VALTYPE_ 684 ExportSysPwrDmnd_W : 1;
SIG_VALTYPE_ 684 MaxImportSysPwrDmnd_W : 1;
SIG_VALTYPE_ 683 ImportSysPwrDmnd_W : 1;
SIG_VALTYPE_ 683 MaxTotalSysPwrDmnd_W : 1;
SIG_VALTYPE_ 682 TotalSysPwrDmnd_W : 1;
SIG_VALTYPE_ 682 ExportReactEnrgy_kVArh : 1;
SIG_VALTYPE_ 681 ImportReactEnrgy_kVArh : 1;
SIG_VALTYPE_ 681 ExportActEnrgy_kWh : 1;
SIG_VALTYPE_ 680 ImportActEnrgy_kWh : 1;
SIG_VALTYPE_ 680 Frequency_Hz : 1;
SIG_VALTYPE_ 679 PwrFctr : 1;
SIG_VALTYPE_ 679 ReactPwr_VAr : 1;
SIG_VALTYPE_ 678 ActivePwr_W : 1;
SIG_VALTYPE_ 678 AprntPwr_VA : 1;
SIG_VALTYPE_ 677 Current_A : 1;
SIG_VALTYPE_ 677 Voltage_V : 1;
SIG_VALTYPE_ 698 TotalReactEnrgy_kVArh : 1;
SIG_VALTYPE_ 697 TotalActvEnergy_kWh : 1;
SIG_VALTYPE_ 697 MaxCurrDmnd_A : 1;
SIG_VALTYPE_ 696 CurrDmnd_A : 1;
SIG_VALTYPE_ 696 MaxExportSysPwrDmnd_W : 1;
SIG_VALTYPE_ 695 ExportSysPwrDmnd_W : 1;
SIG_VALTYPE_ 695 MaxImportSysPwrDmnd_W : 1;
SIG_VALTYPE_ 694 ImportSysPwrDmnd_W : 1;
SIG_VALTYPE_ 694 MaxTotalSysPwrDmnd_W : 1;
SIG_VALTYPE_ 693 TotalSysPwrDmnd_W : 1;
SIG_VALTYPE_ 693 ExportReactEnrgy_kVArh : 1;
SIG_VALTYPE_ 692 ImportReactEnrgy_kVArh : 1;
SIG_VALTYPE_ 692 ExportActEnrgy_kWh : 1;
SIG_VALTYPE_ 691 ImportActEnrgy_kWh : 1;
SIG_VALTYPE_ 691 Frequency_Hz : 1;
SIG_VALTYPE_ 690 PwrFctr : 1;
SIG_VALTYPE_ 690 ReactPwr_VAr : 1;
SIG_VALTYPE_ 689 ActivePwr_W : 1;
SIG_VALTYPE_ 689 AprntPwr_VA : 1;
SIG_VALTYPE_ 688 Current_A : 1;
SIG_VALTYPE_ 688 Voltage_V : 1;
SIG_VALTYPE_ 709 TotalReactEnrgy_kVArh : 1;
SIG_VALTYPE_ 708 TotalActvEnergy_kWh : 1;
SIG_VALTYPE_ 708 MaxCurrDmnd_A : 1;
SIG_VALTYPE_ 707 CurrDmnd_A : 1;
SIG_VALTYPE_ 707 MaxExportSysPwrDmnd_W : 1;
SIG_VALTYPE_ 706 ExportSysPwrDmnd_W : 1;
SIG_VALTYPE_ 706 MaxImportSysPwrDmnd_W : 1;
SIG_VALTYPE_ 705 ImportSysPwrDmnd_W : 1;
SIG_VALTYPE_ 705 MaxTotalSysPwrDmnd_W : 1;
SIG_VALTYPE_ 704 TotalSysPwrDmnd_W : 1;
SIG_VALTYPE_ 704 ExportReactEnrgy_kVArh : 1;
SIG_VALTYPE_ 703 ImportReactEnrgy_kVArh : 1;
SIG_VALTYPE_ 703 ExportActEnrgy_kWh : 1;
SIG_VALTYPE_ 702 ImportActEnrgy_kWh : 1;
SIG_VALTYPE_ 702 Frequency_Hz : 1;
SIG_VALTYPE_ 701 PwrFctr : 1;
SIG_VALTYPE_ 701 ReactPwr_VAr : 1;
SIG_VALTYPE_ 700 ActivePwr_W : 1;
SIG_VALTYPE_ 700 AprntPwr_VA : 1;
SIG_VALTYPE_ 699 Current_A : 1;
SIG_VALTYPE_ 699 Voltage_V : 1;
SIG_VALTYPE_ 720 TotalReactEnrgy_kVArh : 1;
SIG_VALTYPE_ 719 TotalActvEnergy_kWh : 1;
SIG_VALTYPE_ 719 MaxCurrDmnd_A : 1;
SIG_VALTYPE_ 718 CurrDmnd_A : 1;
SIG_VALTYPE_ 718 MaxExportSysPwrDmnd_W : 1;
SIG_VALTYPE_ 717 ExportSysPwrDmnd_W : 1;
SIG_VALTYPE_ 717 MaxImportSysPwrDmnd_W : 1;
SIG_VALTYPE_ 716 ImportSysPwrDmnd_W : 1;
SIG_VALTYPE_ 716 MaxTotalSysPwrDmnd_W : 1;
SIG_VALTYPE_ 715 TotalSysPwrDmnd_W : 1;
SIG_VALTYPE_ 715 ExportReactEnrgy_kVArh : 1;
SIG_VALTYPE_ 714 ImportReactEnrgy_kVArh : 1;
SIG_VALTYPE_ 714 ExportActEnrgy_kWh : 1;
SIG_VALTYPE_ 713 ImportActEnrgy_kWh : 1;
SIG_VALTYPE_ 713 Frequency_Hz : 1;
SIG_VALTYPE_ 712 PwrFctr : 1;
SIG_VALTYPE_ 712 ReactPwr_VAr : 1;
SIG_VALTYPE_ 711 ActivePwr_W : 1;
SIG_VALTYPE_ 711 AprntPwr_VA : 1;
SIG_VALTYPE_ 710 Current_A : 1;
SIG_VALTYPE_ 710 Voltage_V : 1;
